VERSION ""

NS_ :

BS_:

BU_: Charger BMS

BO_ 2552626942 DM6: 1785 Vector__XXX

BO_ 2552561406 DM5: 0 Vector__XXX

BO_ 2552495870 DM4: 0 Vector__XXX

BO_ 2552430334 DM3: 2 Vector__XXX

BO_ 2552364798 DM2: 1785 Vector__XXX

BO_ 2552299262 DM1: 1785 Vector__XXX

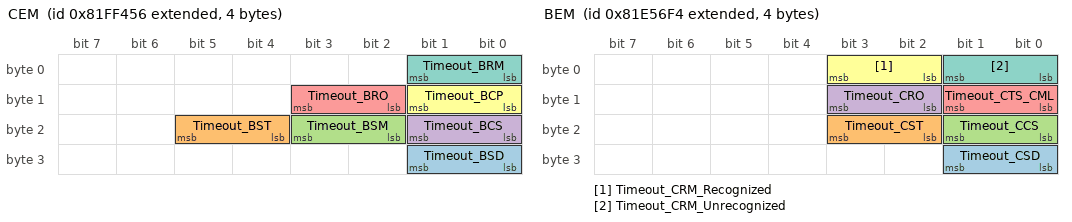
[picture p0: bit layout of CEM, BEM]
BO_ 2283795542 CEM: 4 Charger
 SG_ Timeout_BSD : 24|2@1+ (1,0) [0|3] ""  BMS
 SG_ Timeout_BST : 20|2@1+ (1,0) [0|3] ""  BMS
 SG_ Timeout_BSM : 18|2@1+ (1,0) [0|3] ""  BMS
 SG_ Timeout_BCS : 16|2@1+ (1,0) [0|3] ""  BMS
 SG_ Timeout_BRO : 10|2@1+ (1,0) [0|3] ""  BMS
 SG_ Timeout_BCP : 8|2@1+ (1,0) [0|3] ""  BMS
 SG_ Timeout_BRM : 0|2@1+ (1,0) [0|3] ""  BMS

BO_ 2283689716 BEM: 4 BMS
 SG_ Timeout_CSD : 24|2@1+ (1,0) [0|3] ""  Charger
 SG_ Timeout_CST : 18|2@1+ (1,0) [0|3] ""  Charger
 SG_ Timeout_CCS : 16|2@1+ (1,0) [0|3] ""  Charger
 SG_ Timeout_CRO : 10|2@1+ (1,0) [0|3] ""  Charger
 SG_ Timeout_CTS_CML : 8|2@1+ (1,0) [0|3] ""  Charger
 SG_ Timeout_CRM_Recognized : 2|2@1+ (1,0) [0|3] ""  Charger
 SG_ Timeout_CRM_Unrecognized : 0|2@1+ (1,0) [0|3] ""  Charger

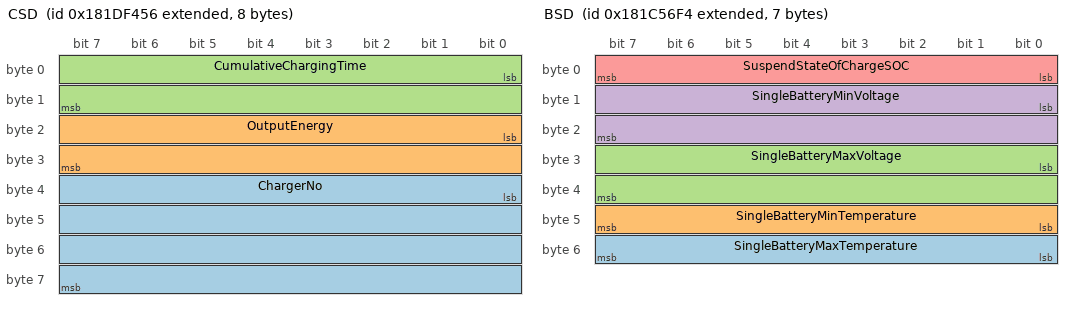
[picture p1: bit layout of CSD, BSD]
BO_ 2552099926 CSD: 8 Charger
 SG_ ChargerNo : 32|32@1+ (1,1) [1|4294967296] ""  BMS
 SG_ OutputEnergy : 16|16@1+ (0.1,0) [0|1000] "kWh"  BMS
 SG_ CumulativeChargingTime : 0|16@1+ (1,0) [0|600] "min"  BMS

BO_ 2551994100 BSD: 7 BMS
 SG_ SingleBatteryMaxTemperature : 48|8@1+ (1,-50) [-50|200] "°C"  Charger
 SG_ SingleBatteryMinTemperature : 40|8@1+ (1,-50) [-50|200] "°C"  Charger
 SG_ SingleBatteryMaxVoltage : 24|16@1+ (0.01,0) [0|24] "V"  Charger
 SG_ SingleBatteryMinVoltage : 8|16@1+ (0.01,0) [0|24] "V"  Charger
 SG_ SuspendStateOfChargeSOC : 0|8@1+ (1,0) [0|100] "%"  Charger

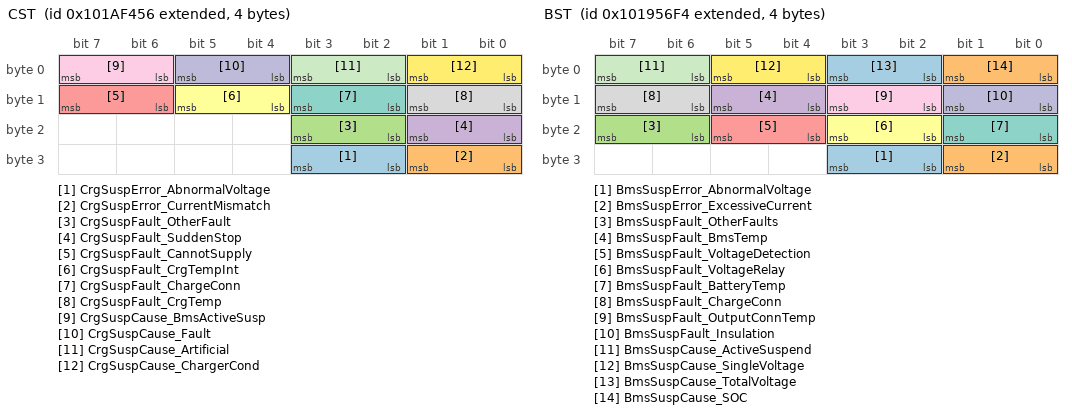
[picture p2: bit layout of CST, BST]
BO_ 2417685590 CST: 4 Charger
 SG_ CrgSuspError_AbnormalVoltage : 26|2@1+ (1,0) [0|3] ""  BMS
 SG_ CrgSuspError_CurrentMismatch : 24|2@1+ (1,0) [0|3] ""  BMS
 SG_ CrgSuspFault_OtherFault : 18|2@1+ (1,0) [0|3] ""  BMS
 SG_ CrgSuspFault_SuddenStop : 16|2@1+ (1,0) [0|3] ""  BMS
 SG_ CrgSuspFault_CannotSupply : 14|2@1+ (1,0) [0|3] ""  BMS
 SG_ CrgSuspFault_CrgTempInt : 12|2@1+ (1,0) [0|3] ""  BMS
 SG_ CrgSuspFault_ChargeConn : 10|2@1+ (1,0) [0|3] ""  BMS
 SG_ CrgSuspFault_CrgTemp : 8|2@1+ (1,0) [0|3] ""  BMS
 SG_ CrgSuspCause_BmsActiveSusp : 6|2@1+ (1,0) [0|3] ""  BMS
 SG_ CrgSuspCause_Fault : 4|2@1+ (1,0) [0|3] ""  BMS
 SG_ CrgSuspCause_Artificial : 2|2@1+ (1,0) [0|3] ""  BMS
 SG_ CrgSuspCause_ChargerCond : 0|2@1+ (1,0) [0|3] ""  BMS

BO_ 2417579764 BST: 4 BMS
 SG_ BmsSuspError_AbnormalVoltage : 26|2@1+ (1,0) [0|3] ""  Charger
 SG_ BmsSuspError_ExcessiveCurrent : 24|2@1+ (1,0) [0|3] ""  Charger
 SG_ BmsSuspFault_OtherFaults : 22|2@1+ (1,0) [0|3] ""  Charger
 SG_ BmsSuspFault_BmsTemp : 12|2@1+ (1,0) [0|3] ""  Charger
 SG_ BmsSuspFault_VoltageDetection : 20|2@1+ (1,0) [0|3] ""  Charger
 SG_ BmsSuspFault_VoltageRelay : 18|2@1+ (1,0) [0|3] ""  Charger
 SG_ BmsSuspFault_BatteryTemp : 16|2@1+ (1,0) [0|3] ""  Charger
 SG_ BmsSuspFault_ChargeConn : 14|2@1+ (1,0) [0|3] ""  Charger
 SG_ BmsSuspFault_OutputConnTemp : 10|2@1+ (1,0) [0|3] ""  Charger
 SG_ BmsSuspFault_Insulation : 8|2@1+ (1,0) [0|3] ""  Charger
 SG_ BmsSuspCause_ActiveSuspend : 6|2@1+ (1,0) [0|3] ""  Charger
 SG_ BmsSuspCause_SingleVoltage : 4|2@1+ (1,0) [0|3] ""  Charger
 SG_ BmsSuspCause_TotalVoltage : 2|2@1+ (1,0) [0|3] ""  Charger
 SG_ BmsSuspCause_SOC : 0|2@1+ (1,0) [0|3] ""  Charger

BO_ 2618775284 BSP: 16 BMS
 SG_ BatteryReserved16 : 120|8@1+ (1,0) [0|255] ""  Charger
 SG_ BatteryReserved15 : 112|8@1+ (1,0) [0|255] ""  Charger
 SG_ BatteryReserved14 : 104|8@1+ (1,0) [0|255] ""  Charger
 SG_ BatteryReserved13 : 96|8@1+ (1,0) [0|255] ""  Charger
 SG_ BatteryReserved12 : 88|8@1+ (1,0) [0|255] ""  Charger
 SG_ BatteryReserved11 : 80|8@1+ (1,0) [0|255] ""  Charger
 SG_ BatteryReserved10 : 72|8@1+ (1,0) [0|255] ""  Charger
 SG_ BatteryReserved09 : 64|8@1+ (1,0) [0|255] ""  Charger
 SG_ BatteryReserved08 : 56|8@1+ (1,0) [0|255] ""  Charger
 SG_ BatteryReserved07 : 48|8@1+ (1,0) [0|255] ""  Charger
 SG_ BatteryReserved06 : 40|8@1+ (1,0) [0|255] ""  Charger
 SG_ BatteryReserved05 : 32|8@1+ (1,0) [0|255] ""  Charger
 SG_ BatteryReserved04 : 24|8@1+ (1,0) [0|255] ""  Charger
 SG_ BatteryReserved03 : 16|8@1+ (1,0) [0|255] ""  Charger
 SG_ BatteryReserved02 : 8|8@1+ (1,0) [0|255] ""  Charger
 SG_ BatteryReserved01 : 0|8@1+ (1,0) [0|255] ""  Charger

BO_ 2618709748 BMT: 128 BMS
 SG_ BatteryTemperature128 : 1016|8@1+ (1,-50) [-50|200] "°C"  Charger
 SG_ BatteryTemperature127 : 1008|8@1+ (1,-50) [-50|200] "°C"  Charger
 SG_ BatteryTemperature126 : 1000|8@1+ (1,-50) [-50|200] "°C"  Charger
 SG_ BatteryTemperature125 : 992|8@1+ (1,-50) [-50|200] "°C"  Charger
 SG_ BatteryTemperature124 : 984|8@1+ (1,-50) [-50|200] "°C"  Charger
 SG_ BatteryTemperature123 : 976|8@1+ (1,-50) [-50|200] "°C"  Charger
 SG_ BatteryTemperature122 : 968|8@1+ (1,-50) [-50|200] "°C"  Charger
 SG_ BatteryTemperature121 : 960|8@1+ (1,-50) [-50|200] "°C"  Charger
 SG_ BatteryTemperature120 : 952|8@1+ (1,-50) [-50|200] "°C"  Charger
 SG_ BatteryTemperature119 : 944|8@1+ (1,-50) [-50|200] "°C"  Charger
 SG_ BatteryTemperature118 : 936|8@1+ (1,-50) [-50|200] "°C"  Charger
 SG_ BatteryTemperature117 : 928|8@1+ (1,-50) [-50|200] "°C"  Charger
 SG_ BatteryTemperature116 : 920|8@1+ (1,-50) [-50|200] "°C"  Charger
 SG_ BatteryTemperature115 : 912|8@1+ (1,-50) [-50|200] "°C"  Charger
 SG_ BatteryTemperature114 : 904|8@1+ (1,-50) [-50|200] "°C"  Charger
 SG_ BatteryTemperature113 : 896|8@1+ (1,-50) [-50|200] "°C"  Charger
 SG_ BatteryTemperature112 : 888|8@1+ (1,-50) [-50|200] "°C"  Charger
 SG_ BatteryTemperature111 : 880|8@1+ (1,-50) [-50|200] "°C"  Charger
 SG_ BatteryTemperature110 : 872|8@1+ (1,-50) [-50|200] "°C"  Charger
 SG_ BatteryTemperature109 : 864|8@1+ (1,-50) [-50|200] "°C"  Charger
 SG_ BatteryTemperature108 : 856|8@1+ (1,-50) [-50|200] "°C"  Charger
 SG_ BatteryTemperature107 : 848|8@1+ (1,-50) [-50|200] "°C"  Charger
 SG_ BatteryTemperature106 : 840|8@1+ (1,-50) [-50|200] "°C"  Charger
 SG_ BatteryTemperature105 : 832|8@1+ (1,-50) [-50|200] "°C"  Charger
 SG_ BatteryTemperature104 : 824|8@1+ (1,-50) [-50|200] "°C"  Charger
 SG_ BatteryTemperature103 : 816|8@1+ (1,-50) [-50|200] "°C"  Charger
 SG_ BatteryTemperature102 : 808|8@1+ (1,-50) [-50|200] "°C"  Charger
 SG_ BatteryTemperature101 : 800|8@1+ (1,-50) [-50|200] "°C"  Charger
 SG_ BatteryTemperature100 : 792|8@1+ (1,-50) [-50|200] "°C"  Charger
 SG_ BatteryTemperature099 : 784|8@1+ (1,-50) [-50|200] "°C"  Charger
 SG_ BatteryTemperature098 : 776|8@1+ (1,-50) [-50|200] "°C"  Charger
 SG_ BatteryTemperature097 : 768|8@1+ (1,-50) [-50|200] "°C"  Charger
 SG_ BatteryTemperature096 : 760|8@1+ (1,-50) [-50|200] "°C"  Charger
 SG_ BatteryTemperature095 : 752|8@1+ (1,-50) [-50|200] "°C"  Charger
 SG_ BatteryTemperature094 : 744|8@1+ (1,-50) [-50|200] "°C"  Charger
 SG_ BatteryTemperature093 : 736|8@1+ (1,-50) [-50|200] "°C"  Charger
 SG_ BatteryTemperature092 : 728|8@1+ (1,-50) [-50|200] "°C"  Charger
 SG_ BatteryTemperature091 : 720|8@1+ (1,-50) [-50|200] "°C"  Charger
 SG_ BatteryTemperature090 : 712|8@1+ (1,-50) [-50|200] "°C"  Charger
 SG_ BatteryTemperature089 : 704|8@1+ (1,-50) [-50|200] "°C"  Charger
 SG_ BatteryTemperature088 : 696|8@1+ (1,-50) [-50|200] "°C"  Charger
 SG_ BatteryTemperature087 : 688|8@1+ (1,-50) [-50|200] "°C"  Charger
 SG_ BatteryTemperature086 : 680|8@1+ (1,-50) [-50|200] "°C"  Charger
 SG_ BatteryTemperature085 : 672|8@1+ (1,-50) [-50|200] "°C"  Charger
 SG_ BatteryTemperature084 : 664|8@1+ (1,-50) [-50|200] "°C"  Charger
 SG_ BatteryTemperature083 : 656|8@1+ (1,-50) [-50|200] "°C"  Charger
 SG_ BatteryTemperature082 : 648|8@1+ (1,-50) [-50|200] "°C"  Charger
 SG_ BatteryTemperature081 : 640|8@1+ (1,-50) [-50|200] "°C"  Charger
 SG_ BatteryTemperature080 : 632|8@1+ (1,-50) [-50|200] "°C"  Charger
 SG_ BatteryTemperature079 : 624|8@1+ (1,-50) [-50|200] "°C"  Charger
 SG_ BatteryTemperature078 : 616|8@1+ (1,-50) [-50|200] "°C"  Charger
 SG_ BatteryTemperature077 : 608|8@1+ (1,-50) [-50|200] "°C"  Charger
 SG_ BatteryTemperature076 : 600|8@1+ (1,-50) [-50|200] "°C"  Charger
 SG_ BatteryTemperature075 : 592|8@1+ (1,-50) [-50|200] "°C"  Charger
 SG_ BatteryTemperature074 : 584|8@1+ (1,-50) [-50|200] "°C"  Charger
 SG_ BatteryTemperature073 : 576|8@1+ (1,-50) [-50|200] "°C"  Charger
 SG_ BatteryTemperature072 : 568|8@1+ (1,-50) [-50|200] "°C"  Charger
 SG_ BatteryTemperature071 : 560|8@1+ (1,-50) [-50|200] "°C"  Charger
 SG_ BatteryTemperature070 : 552|8@1+ (1,-50) [-50|200] "°C"  Charger
 SG_ BatteryTemperature069 : 544|8@1+ (1,-50) [-50|200] "°C"  Charger
 SG_ BatteryTemperature068 : 536|8@1+ (1,-50) [-50|200] "°C"  Charger
 SG_ BatteryTemperature067 : 528|8@1+ (1,-50) [-50|200] "°C"  Charger
 SG_ BatteryTemperature066 : 520|8@1+ (1,-50) [-50|200] "°C"  Charger
 SG_ BatteryTemperature065 : 512|8@1+ (1,-50) [-50|200] "°C"  Charger
 SG_ BatteryTemperature064 : 504|8@1+ (1,-50) [-50|200] "°C"  Charger
 SG_ BatteryTemperature063 : 496|8@1+ (1,-50) [-50|200] "°C"  Charger
 SG_ BatteryTemperature062 : 488|8@1+ (1,-50) [-50|200] "°C"  Charger
 SG_ BatteryTemperature061 : 480|8@1+ (1,-50) [-50|200] "°C"  Charger
 SG_ BatteryTemperature060 : 472|8@1+ (1,-50) [-50|200] "°C"  Charger
 SG_ BatteryTemperature059 : 464|8@1+ (1,-50) [-50|200] "°C"  Charger
 SG_ BatteryTemperature058 : 456|8@1+ (1,-50) [-50|200] "°C"  Charger
 SG_ BatteryTemperature057 : 448|8@1+ (1,-50) [-50|200] "°C"  Charger
 SG_ BatteryTemperature056 : 440|8@1+ (1,-50) [-50|200] "°C"  Charger
 SG_ BatteryTemperature055 : 432|8@1+ (1,-50) [-50|200] "°C"  Charger
 SG_ BatteryTemperature054 : 424|8@1+ (1,-50) [-50|200] "°C"  Charger
 SG_ BatteryTemperature053 : 416|8@1+ (1,-50) [-50|200] "°C"  Charger
 SG_ BatteryTemperature052 : 408|8@1+ (1,-50) [-50|200] "°C"  Charger
 SG_ BatteryTemperature051 : 400|8@1+ (1,-50) [-50|200] "°C"  Charger
 SG_ BatteryTemperature050 : 392|8@1+ (1,-50) [-50|200] "°C"  Charger
 SG_ BatteryTemperature049 : 384|8@1+ (1,-50) [-50|200] "°C"  Charger
 SG_ BatteryTemperature048 : 376|8@1+ (1,-50) [-50|200] "°C"  Charger
 SG_ BatteryTemperature047 : 368|8@1+ (1,-50) [-50|200] "°C"  Charger
 SG_ BatteryTemperature046 : 360|8@1+ (1,-50) [-50|200] "°C"  Charger
 SG_ BatteryTemperature045 : 352|8@1+ (1,-50) [-50|200] "°C"  Charger
 SG_ BatteryTemperature044 : 344|8@1+ (1,-50) [-50|200] "°C"  Charger
 SG_ BatteryTemperature043 : 336|8@1+ (1,-50) [-50|200] "°C"  Charger
 SG_ BatteryTemperature042 : 328|8@1+ (1,-50) [-50|200] "°C"  Charger
 SG_ BatteryTemperature041 : 320|8@1+ (1,-50) [-50|200] "°C"  Charger
 SG_ BatteryTemperature040 : 312|8@1+ (1,-50) [-50|200] "°C"  Charger
 SG_ BatteryTemperature039 : 304|8@1+ (1,-50) [-50|200] "°C"  Charger
 SG_ BatteryTemperature038 : 296|8@1+ (1,-50) [-50|200] "°C"  Charger
 SG_ BatteryTemperature037 : 288|8@1+ (1,-50) [-50|200] "°C"  Charger
 SG_ BatteryTemperature036 : 280|8@1+ (1,-50) [-50|200] "°C"  Charger
 SG_ BatteryTemperature035 : 272|8@1+ (1,-50) [-50|200] "°C"  Charger
 SG_ BatteryTemperature034 : 264|8@1+ (1,-50) [-50|200] "°C"  Charger
 SG_ BatteryTemperature033 : 256|8@1+ (1,-50) [-50|200] "°C"  Charger
 SG_ BatteryTemperature032 : 248|8@1+ (1,-50) [-50|200] "°C"  Charger
 SG_ BatteryTemperature031 : 240|8@1+ (1,-50) [-50|200] "°C"  Charger
 SG_ BatteryTemperature030 : 232|8@1+ (1,-50) [-50|200] "°C"  Charger
 SG_ BatteryTemperature029 : 224|8@1+ (1,-50) [-50|200] "°C"  Charger
 SG_ BatteryTemperature028 : 216|8@1+ (1,-50) [-50|200] "°C"  Charger
 SG_ BatteryTemperature027 : 208|8@1+ (1,-50) [-50|200] "°C"  Charger
 SG_ BatteryTemperature026 : 200|8@1+ (1,-50) [-50|200] "°C"  Charger
 SG_ BatteryTemperature025 : 192|8@1+ (1,-50) [-50|200] "°C"  Charger
 SG_ BatteryTemperature024 : 184|8@1+ (1,-50) [-50|200] "°C"  Charger
 SG_ BatteryTemperature023 : 176|8@1+ (1,-50) [-50|200] "°C"  Charger
 SG_ BatteryTemperature022 : 168|8@1+ (1,-50) [-50|200] "°C"  Charger
 SG_ BatteryTemperature021 : 160|8@1+ (1,-50) [-50|200] "°C"  Charger
 SG_ BatteryTemperature020 : 152|8@1+ (1,-50) [-50|200] "°C"  Charger
 SG_ BatteryTemperature019 : 144|8@1+ (1,-50) [-50|200] "°C"  Charger
 SG_ BatteryTemperature018 : 136|8@1+ (1,-50) [-50|200] "°C"  Charger
 SG_ BatteryTemperature017 : 128|8@1+ (1,-50) [-50|200] "°C"  Charger
 SG_ BatteryTemperature016 : 120|8@1+ (1,-50) [-50|200] "°C"  Charger
 SG_ BatteryTemperature015 : 112|8@1+ (1,-50) [-50|200] "°C"  Charger
 SG_ BatteryTemperature014 : 104|8@1+ (1,-50) [-50|200] "°C"  Charger
 SG_ BatteryTemperature013 : 96|8@1+ (1,-50) [-50|200] "°C"  Charger
 SG_ BatteryTemperature012 : 88|8@1+ (1,-50) [-50|200] "°C"  Charger
 SG_ BatteryTemperature011 : 80|8@1+ (1,-50) [-50|200] "°C"  Charger
 SG_ BatteryTemperature010 : 72|8@1+ (1,-50) [-50|200] "°C"  Charger
 SG_ BatteryTemperature009 : 64|8@1+ (1,-50) [-50|200] "°C"  Charger
 SG_ BatteryTemperature008 : 56|8@1+ (1,-50) [-50|200] "°C"  Charger
 SG_ BatteryTemperature007 : 48|8@1+ (1,-50) [-50|200] "°C"  Charger
 SG_ BatteryTemperature006 : 40|8@1+ (1,-50) [-50|200] "°C"  Charger
 SG_ BatteryTemperature005 : 32|8@1+ (1,-50) [-50|200] "°C"  Charger
 SG_ BatteryTemperature004 : 24|8@1+ (1,-50) [-50|200] "°C"  Charger
 SG_ BatteryTemperature003 : 16|8@1+ (1,-50) [-50|200] "°C"  Charger
 SG_ BatteryTemperature002 : 8|8@1+ (1,-50) [-50|200] "°C"  Charger
 SG_ BatteryTemperature001 : 0|8@1+ (1,-50) [-50|200] "°C"  Charger

CM_ "J1939 messages without part -7x";
CM_ BO_ 2552626942 "Freeze frame parameter

Attention: Incomplete signal set!";
CM_ BO_ 2552561406 "Clear/reset of historic fault code";
CM_ BO_ 2552495870 "Clear/reset of current fault code";
CM_ BO_ 2552430334 "Diagnose ready

Attention: Incomplete signal set!";
CM_ BO_ 2552364798 "Historic fault code

Attention: Incomplete signal set!";
CM_ BO_ 2552299262 "Current fault code

Attention: Incomplete signal set!";
CM_ BO_ 2283795542 "Charger's error message";
CM_ SG_ 2283795542 Timeout_BSD "Receive timeout of BMS's charging statistics message (<00>:=normal; <01>:=timeout; <10>:=untrusted state)";
CM_ SG_ 2283795542 Timeout_BST "Receive timeout of BMS's charging suspension message (<00>:=normal; <01>:=timeout; <10>:=untrusted state)";
CM_ SG_ 2283795542 Timeout_BSM "Receive timeout of battery charging requirement message (<00>:=normal; <01>:=timeout; <10>:=untrusted state)";
CM_ SG_ 2283795542 Timeout_BCS "Receive timeout of overall battery charging state message (<00>:=normal; <01>:=timeout; <10>:=untrusted state)";
CM_ SG_ 2283795542 Timeout_BRO "Receive timeout of BMS's charging preparation completion message (<00>:=normal; <01>:=timeout; <10>:=untrusted state)";
CM_ SG_ 2283795542 Timeout_BCP "Receive timeout of battery charging parameter message (<00>:=normal; <01>:=timeout; <10>:=untrusted state)";
CM_ SG_ 2283795542 Timeout_BRM "Receive timeout of BMS and vehicle recognition message (<00>:=normal; <01>:=timeout; <10>:=untrusted state)";
CM_ BO_ 2283689716 "BMS's error message";
CM_ SG_ 2283689716 Timeout_CSD "Receive timeout of charger's charging statistics message (<00>:=normal; <01>:=timeout; <10>:=untrusted state)";
CM_ SG_ 2283689716 Timeout_CST "Receive timeout of charger's charging suspension message (<00>:=normal; <01>:=timeout; <10>:=untrusted state)";
CM_ SG_ 2283689716 Timeout_CCS "Receive  timeout  of  charger's  charging  state  message (<00>:=normal; <01>:=timeout; <10>:=untrusted state)";
CM_ SG_ 2283689716 Timeout_CRO "Receive  timeout  of  charger's  charging  preparation  completion message (<00>:=normal; <01>:=timeout; <10>:=untrusted state)";
CM_ SG_ 2283689716 Timeout_CTS_CML "Receive  timeout  of  charger  time  synchronization  message  and charger  maximum  output  capacity  message  (<00>:=normal; <01>:=timeout; <10>:=untrusted state)";
CM_ SG_ 2283689716 Timeout_CRM_Recognized "Receive timeout of SPN2560=0×AA charger recognition message (<00>:=normal; <01>:=timeout; <10>:=untrusted state)";
CM_ SG_ 2283689716 Timeout_CRM_Unrecognized "Receive timeout of SPN2560=0×00 charger recognition message (<00>:=normal; <01>:=timeout; <10>:=untrusted state)";
CM_ BO_ 2552099926 "Charger's statistical data";
CM_ SG_ 2552099926 ChargerNo "Charger No., 1/bit; 1 offset; data scope: 0~0xFFFFFFFF";
CM_ SG_ 2552099926 OutputEnergy "Output energy (kW·h)";
CM_ SG_ 2552099926 CumulativeChargingTime "Cumulative charging time (min)";
CM_ BO_ 2551994100 "BMS statistical data";
CM_ SG_ 2551994100 SingleBatteryMaxTemperature "Maximum temperature of power storage battery (°C)";
CM_ SG_ 2551994100 SingleBatteryMinTemperature "Minimum temperature of power storage battery (°C)";
CM_ SG_ 2551994100 SingleBatteryMaxVoltage "Maximum voltage of single power storage battery (V)";
CM_ SG_ 2551994100 SingleBatteryMinVoltage "Minimum voltage of single power storage battery (V)";
CM_ SG_ 2551994100 SuspendStateOfChargeSOC "Suspend state-of-charge SOC (%)";
CM_ BO_ 2417685590 "Charger suspending charging";
CM_ SG_ 2417685590 CrgSuspError_AbnormalVoltage "Error cause for charger suspending charging

voltage is abnormal";
CM_ SG_ 2417685590 CrgSuspError_CurrentMismatch "Error cause for charger suspending charging

current mismatching";
CM_ SG_ 2417685590 CrgSuspFault_OtherFault "Fault cause for charger suspending charging

other fault";
CM_ SG_ 2417685590 CrgSuspFault_SuddenStop "Fault cause for charger suspending charging

sudden stop of charger";
CM_ SG_ 2417685590 CrgSuspFault_CannotSupply "Fault cause for charger suspending charging

the required electric quantity cannot be transmitted";
CM_ SG_ 2417685590 CrgSuspFault_CrgTempInt "Fault cause for charger suspending charging

charger is over-temperature at the internal part";
CM_ SG_ 2417685590 CrgSuspFault_ChargeConn "Fault cause for charger suspending charging

charging connector fault";
CM_ SG_ 2417685590 CrgSuspFault_CrgTemp "Fault cause for charger suspending charging

charger over-temperature";
CM_ SG_ 2417685590 CrgSuspCause_BmsActiveSusp "Cause for charger suspending charging - BMS actively suspends";
CM_ SG_ 2417685590 CrgSuspCause_Fault "Cause for charger suspending charging - fault suspension";
CM_ SG_ 2417685590 CrgSuspCause_Artificial "Cause for charger suspending charging - suspends artificially";
CM_ SG_ 2417685590 CrgSuspCause_ChargerCond "Cause for charger suspending charging - suspends due to reaching the condition set by charger";
CM_ BO_ 2417579764 "BMS suspending charging";
CM_ SG_ 2417579764 BmsSuspError_AbnormalVoltage "Error cause for BMS suspending charging

voltage is abnormal";
CM_ SG_ 2417579764 BmsSuspError_ExcessiveCurrent "Error cause for BMS suspending charging

excessive current";
CM_ SG_ 2417579764 BmsSuspFault_OtherFaults "Fault cause for BMS suspending charging

other faults";
CM_ SG_ 2417579764 BmsSuspFault_BmsTemp "Fault cause for BMS suspending charging

BMS component and output connector over-temperature";
CM_ SG_ 2417579764 BmsSuspFault_VoltageDetection "Fault cause for BMS suspending charging

voltage detection fault at check point 2";
CM_ SG_ 2417579764 BmsSuspFault_VoltageRelay "Fault cause for BMS suspending charging

high voltage relay fault";
CM_ SG_ 2417579764 BmsSuspFault_BatteryTemp "Fault cause for BMS suspending charging

battery set over-temperature";
CM_ SG_ 2417579764 BmsSuspFault_ChargeConn "Fault cause for BMS suspending charging

charging connector fault";
CM_ SG_ 2417579764 BmsSuspFault_OutputConnTemp "Fault cause for BMS suspending charging

output connector over-temperature";
CM_ SG_ 2417579764 BmsSuspFault_Insulation "Fault cause for BMS suspending charging

insulation fault";
CM_ SG_ 2417579764 BmsSuspCause_ActiveSuspend "Cause for BMS suspending charging

charger actively suspends";
CM_ SG_ 2417579764 BmsSuspCause_SingleVoltage "Cause for BMS suspending charging

reach the setting value of single voltage";
CM_ SG_ 2417579764 BmsSuspCause_TotalVoltage "Cause for BMS suspending charging

reach the setting value of total voltage ";
CM_ SG_ 2417579764 BmsSuspCause_SOC "Cause for BMS suspending charging

reach the required SOC target value";
CM_ BO_ 2618775284 "Reserved message of power storage battery";
CM_ SG_ 2618775284 BatteryReserved16 "Power storage battery reserved field 16";
CM_ SG_ 2618775284 BatteryReserved15 "Power storage battery reserved field 15";
CM_ SG_ 2618775284 BatteryReserved14 "Power storage battery reserved field 14";
CM_ SG_ 2618775284 BatteryReserved13 "Power storage battery reserved field 13";
CM_ SG_ 2618775284 BatteryReserved12 "Power storage battery reserved field 12";
CM_ SG_ 2618775284 BatteryReserved11 "Power storage battery reserved field 11";
CM_ SG_ 2618775284 BatteryReserved10 "Power storage battery reserved field 10";
CM_ SG_ 2618775284 BatteryReserved09 "Power storage battery reserved field 9";
CM_ SG_ 2618775284 BatteryReserved08 "Power storage battery reserved field 8";
CM_ SG_ 2618775284 BatteryReserved07 "Power storage battery reserved field 7";
CM_ SG_ 2618775284 BatteryReserved06 "Power storage battery reserved field 6";
CM_ SG_ 2618775284 BatteryReserved05 "Power storage battery reserved field 5";
CM_ SG_ 2618775284 BatteryReserved04 "Power storage battery reserved field 4";
CM_ SG_ 2618775284 BatteryReserved03 "Power storage battery reserved field 3";
CM_ SG_ 2618775284 BatteryReserved02 "Power storage battery reserved field 2";
CM_ SG_ 2618775284 BatteryReserved01 "Power storage battery reserved field 1";
CM_ BO_ 2618709748 "Temperature of power storage battery";
CM_ SG_ 2618709748 BatteryTemperature128 "Power storage battery temperature 128";
CM_ SG_ 2618709748 BatteryTemperature127 "Power storage battery temperature 127";
CM_ SG_ 2618709748 BatteryTemperature126 "Power storage battery temperature 126";
CM_ SG_ 2618709748 BatteryTemperature125 "Power storage battery temperature 125";
CM_ SG_ 2618709748 BatteryTemperature124 "Power storage battery temperature 124";
CM_ SG_ 2618709748 BatteryTemperature123 "Power storage battery temperature 123";
CM_ SG_ 2618709748 BatteryTemperature122 "Power storage battery temperature 122";
CM_ SG_ 2618709748 BatteryTemperature121 "Power storage battery temperature 121";
CM_ SG_ 2618709748 BatteryTemperature120 "Power storage battery temperature 120";
CM_ SG_ 2618709748 BatteryTemperature119 "Power storage battery temperature 119";
CM_ SG_ 2618709748 BatteryTemperature118 "Power storage battery temperature 118";
CM_ SG_ 2618709748 BatteryTemperature117 "Power storage battery temperature 117";
CM_ SG_ 2618709748 BatteryTemperature116 "Power storage battery temperature 116";
CM_ SG_ 2618709748 BatteryTemperature115 "Power storage battery temperature 115";
CM_ SG_ 2618709748 BatteryTemperature114 "Power storage battery temperature 114";
CM_ SG_ 2618709748 BatteryTemperature113 "Power storage battery temperature 113";
CM_ SG_ 2618709748 BatteryTemperature112 "Power storage battery temperature 112";
CM_ SG_ 2618709748 BatteryTemperature111 "Power storage battery temperature 111";
CM_ SG_ 2618709748 BatteryTemperature110 "Power storage battery temperature 110";
CM_ SG_ 2618709748 BatteryTemperature109 "Power storage battery temperature 109";
CM_ SG_ 2618709748 BatteryTemperature108 "Power storage battery temperature 108";
CM_ SG_ 2618709748 BatteryTemperature107 "Power storage battery temperature 107";
CM_ SG_ 2618709748 BatteryTemperature106 "Power storage battery temperature 106";
CM_ SG_ 2618709748 BatteryTemperature105 "Power storage battery temperature 105";
CM_ SG_ 2618709748 BatteryTemperature104 "Power storage battery temperature 104";
CM_ SG_ 2618709748 BatteryTemperature103 "Power storage battery temperature 103";
CM_ SG_ 2618709748 BatteryTemperature102 "Power storage battery temperature 102";
CM_ SG_ 2618709748 BatteryTemperature101 "Power storage battery temperature 101";
CM_ SG_ 2618709748 BatteryTemperature100 "Power storage battery temperature 100";
CM_ SG_ 2618709748 BatteryTemperature099 "Power storage battery temperature 99";
CM_ SG_ 2618709748 BatteryTemperature098 "Power storage battery temperature 98";
CM_ SG_ 2618709748 BatteryTemperature097 "Power storage battery temperature 97";
CM_ SG_ 2618709748 BatteryTemperature096 "Power storage battery temperature 96";
CM_ SG_ 2618709748 BatteryTemperature095 "Power storage battery temperature 95";
CM_ SG_ 2618709748 BatteryTemperature094 "Power storage battery temperature 94";
CM_ SG_ 2618709748 BatteryTemperature093 "Power storage battery temperature 93";
CM_ SG_ 2618709748 BatteryTemperature092 "Power storage battery temperature 92";
CM_ SG_ 2618709748 BatteryTemperature091 "Power storage battery temperature 91";
CM_ SG_ 2618709748 BatteryTemperature090 "Power storage battery temperature 90";
CM_ SG_ 2618709748 BatteryTemperature089 "Power storage battery temperature 89";
CM_ SG_ 2618709748 BatteryTemperature088 "Power storage battery temperature 88";
CM_ SG_ 2618709748 BatteryTemperature087 "Power storage battery temperature 87";
CM_ SG_ 2618709748 BatteryTemperature086 "Power storage battery temperature 86";
CM_ SG_ 2618709748 BatteryTemperature085 "Power storage battery temperature 85";
CM_ SG_ 2618709748 BatteryTemperature084 "Power storage battery temperature 84";
CM_ SG_ 2618709748 BatteryTemperature083 "Power storage battery temperature 83";
CM_ SG_ 2618709748 BatteryTemperature082 "Power storage battery temperature 82";
CM_ SG_ 2618709748 BatteryTemperature081 "Power storage battery temperature 81";
CM_ SG_ 2618709748 BatteryTemperature080 "Power storage battery temperature 80";
CM_ SG_ 2618709748 BatteryTemperature079 "Power storage battery temperature 79";
CM_ SG_ 2618709748 BatteryTemperature078 "Power storage battery temperature 78";
CM_ SG_ 2618709748 BatteryTemperature077 "Power storage battery temperature 77";
CM_ SG_ 2618709748 BatteryTemperature076 "Power storage battery temperature 76";
CM_ SG_ 2618709748 BatteryTemperature075 "Power storage battery temperature 75";
CM_ SG_ 2618709748 BatteryTemperature074 "Power storage battery temperature 74";
CM_ SG_ 2618709748 BatteryTemperature073 "Power storage battery temperature 73";
CM_ SG_ 2618709748 BatteryTemperature072 "Power storage battery temperature 72";
CM_ SG_ 2618709748 BatteryTemperature071 "Power storage battery temperature 71";
CM_ SG_ 2618709748 BatteryTemperature070 "Power storage battery temperature 70";
CM_ SG_ 2618709748 BatteryTemperature069 "Power storage battery temperature 69";
CM_ SG_ 2618709748 BatteryTemperature068 "Power storage battery temperature 68";
CM_ SG_ 2618709748 BatteryTemperature067 "Power storage battery temperature 67";
CM_ SG_ 2618709748 BatteryTemperature066 "Power storage battery temperature 66";
CM_ SG_ 2618709748 BatteryTemperature065 "Power storage battery temperature 65";
CM_ SG_ 2618709748 BatteryTemperature064 "Power storage battery temperature 64";
CM_ SG_ 2618709748 BatteryTemperature063 "Power storage battery temperature 63";
CM_ SG_ 2618709748 BatteryTemperature062 "Power storage battery temperature 62";
CM_ SG_ 2618709748 BatteryTemperature061 "Power storage battery temperature 61";
CM_ SG_ 2618709748 BatteryTemperature060 "Power storage battery temperature 60";
CM_ SG_ 2618709748 BatteryTemperature059 "Power storage battery temperature 59";
CM_ SG_ 2618709748 BatteryTemperature058 "Power storage battery temperature 58";
CM_ SG_ 2618709748 BatteryTemperature057 "Power storage battery temperature 57";
CM_ SG_ 2618709748 BatteryTemperature056 "Power storage battery temperature 56";
CM_ SG_ 2618709748 BatteryTemperature055 "Power storage battery temperature 55";
CM_ SG_ 2618709748 BatteryTemperature054 "Power storage battery temperature 54";
CM_ SG_ 2618709748 BatteryTemperature053 "Power storage battery temperature 53";
CM_ SG_ 2618709748 BatteryTemperature052 "Power storage battery temperature 52";
CM_ SG_ 2618709748 BatteryTemperature051 "Power storage battery temperature 51";
CM_ SG_ 2618709748 BatteryTemperature050 "Power storage battery temperature 50";
CM_ SG_ 2618709748 BatteryTemperature049 "Power storage battery temperature 49";
CM_ SG_ 2618709748 BatteryTemperature048 "Power storage battery temperature 48";
CM_ SG_ 2618709748 BatteryTemperature047 "Power storage battery temperature 47";
CM_ SG_ 2618709748 BatteryTemperature046 "Power storage battery temperature 46";
CM_ SG_ 2618709748 BatteryTemperature045 "Power storage battery temperature 45";
CM_ SG_ 2618709748 BatteryTemperature044 "Power storage battery temperature 44";
CM_ SG_ 2618709748 BatteryTemperature043 "Power storage battery temperature 43";
CM_ SG_ 2618709748 BatteryTemperature042 "Power storage battery temperature 42";
CM_ SG_ 2618709748 BatteryTemperature041 "Power storage battery temperature 41";
CM_ SG_ 2618709748 BatteryTemperature040 "Power storage battery temperature 40";
CM_ SG_ 2618709748 BatteryTemperature039 "Power storage battery temperature 39";
CM_ SG_ 2618709748 BatteryTemperature038 "Power storage battery temperature 38";
CM_ SG_ 2618709748 BatteryTemperature037 "Power storage battery temperature 37";
CM_ SG_ 2618709748 BatteryTemperature036 "Power storage battery temperature 36";
CM_ SG_ 2618709748 BatteryTemperature035 "Power storage battery temperature 35";
CM_ SG_ 2618709748 BatteryTemperature034 "Power storage battery temperature 34";
CM_ SG_ 2618709748 BatteryTemperature033 "Power storage battery temperature 33";
CM_ SG_ 2618709748 BatteryTemperature032 "Power storage battery temperature 32";
CM_ SG_ 2618709748 BatteryTemperature031 "Power storage battery temperature 31";
CM_ SG_ 2618709748 BatteryTemperature030 "Power storage battery temperature 30";
CM_ SG_ 2618709748 BatteryTemperature029 "Power storage battery temperature 29";
CM_ SG_ 2618709748 BatteryTemperature028 "Power storage battery temperature 28";
CM_ SG_ 2618709748 BatteryTemperature027 "Power storage battery temperature 27";
CM_ SG_ 2618709748 BatteryTemperature026 "Power storage battery temperature 26";
CM_ SG_ 2618709748 BatteryTemperature025 "Power storage battery temperature 25";
CM_ SG_ 2618709748 BatteryTemperature024 "Power storage battery temperature 24";
CM_ SG_ 2618709748 BatteryTemperature023 "Power storage battery temperature 23";
CM_ SG_ 2618709748 BatteryTemperature022 "Power storage battery temperature 22";
CM_ SG_ 2618709748 BatteryTemperature021 "Power storage battery temperature 21";
CM_ SG_ 2618709748 BatteryTemperature020 "Power storage battery temperature 20";
CM_ SG_ 2618709748 BatteryTemperature019 "Power storage battery temperature 19";
CM_ SG_ 2618709748 BatteryTemperature018 "Power storage battery temperature 18";
CM_ SG_ 2618709748 BatteryTemperature017 "Power storage battery temperature 17";
CM_ SG_ 2618709748 BatteryTemperature016 "Power storage battery temperature 16";
CM_ SG_ 2618709748 BatteryTemperature015 "Power storage battery temperature 15";
CM_ SG_ 2618709748 BatteryTemperature014 "Power storage battery temperature 14";
CM_ SG_ 2618709748 BatteryTemperature013 "Power storage battery temperature 13";
CM_ SG_ 2618709748 BatteryTemperature012 "Power storage battery temperature 12";
CM_ SG_ 2618709748 BatteryTemperature011 "Power storage battery temperature 11";
CM_ SG_ 2618709748 BatteryTemperature010 "Power storage battery temperature 10";
CM_ SG_ 2618709748 BatteryTemperature009 "Power storage battery temperature 9";
CM_ SG_ 2618709748 BatteryTemperature008 "Power storage battery temperature 8";
CM_ SG_ 2618709748 BatteryTemperature007 "Power storage battery temperature 7";
CM_ SG_ 2618709748 BatteryTemperature006 "Power storage battery temperature 6";
CM_ SG_ 2618709748 BatteryTemperature005 "Power storage battery temperature 5";
CM_ SG_ 2618709748 BatteryTemperature004 "Power storage battery temperature 4";
CM_ SG_ 2618709748 BatteryTemperature003 "Power storage battery temperature 3";
CM_ SG_ 2618709748 BatteryTemperature002 "Power storage battery temperature 2";
CM_ SG_ 2618709748 BatteryTemperature001 "Power storage battery temperature 1";
BA_DEF_  "DBName" STRING ;
BA_DEF_ SG_  "SigType" ENUM  "Default","Range","RangeSigned","ASCII","Discrete","Control","ReferencePGN","DTC","StringDelimiter","StringLength","StringLengthControl","MessageCounter","MessageChecksum";
BA_DEF_ SG_  "GenSigStartValue" INT 0 2147483647;
BA_DEF_ SG_  "GenSigSendType" ENUM  "Cyclic","OnWrite","OnWriteWithRepetition","OnChange","OnChangeWithRepetition","IfActive","IfActiveWithRepetition","NoSigSendType";
BA_DEF_ SG_  "GenSigILSupport" ENUM  "No","Yes";
BA_DEF_ SG_  "GenSigEVName" STRING ;
BA_DEF_ SG_  "SPN" INT 0 524287;
BA_DEF_ BO_  "TpJ1939VarDlc" ENUM  "No","Yes";
BA_DEF_ BO_  "GenMsgILSupport" ENUM  "No","Yes";
BA_DEF_ BO_  "GenMsgRequestable" INT 0 1;
BA_DEF_ BO_  "GenMsgSendType" ENUM  "cyclic","NotUsed","NotUsed","NotUsed","NotUsed","NotUsed","NotUsed","IfActive","noMsgSendType";
BA_DEF_ BO_  "VFrameFormat" ENUM  "StandardCAN","ExtendedCAN","reserved","J1939PG";
BA_DEF_ BO_  "GenMsgCycleTime" INT 0 3600000;
BA_DEF_ BU_  "NmStationAddress" INT 0 255;
BA_DEF_ BU_  "NmJ1939Function" INT 0 255;
BA_DEF_ BU_  "NmJ1939ManufacturerCode" INT 0 2047;
BA_DEF_  "SAE_J1939_DA_SpecVersion" STRING ;
BA_DEF_  "SAE_J1939_81_SpecVersion" STRING ;
BA_DEF_  "DatabaseVersion" STRING ;
BA_DEF_  "BusType" STRING ;
BA_DEF_  "ProtocolType" STRING ;
BA_DEF_  "SAE_J1939_21_SpecVersion" STRING ;
BA_DEF_DEF_  "DBName" "";
BA_DEF_DEF_  "SigType" "Default";
BA_DEF_DEF_  "GenSigStartValue" 0;
BA_DEF_DEF_  "GenSigSendType" "NoSigSendType";
BA_DEF_DEF_  "GenSigILSupport" "Yes";
BA_DEF_DEF_  "GenSigEVName" "Env@Nodename_@Signame";
BA_DEF_DEF_  "SPN" 0;
BA_DEF_DEF_  "TpJ1939VarDlc" "No";
BA_DEF_DEF_  "GenMsgILSupport" "Yes";
BA_DEF_DEF_  "GenMsgRequestable" 1;
BA_DEF_DEF_  "GenMsgSendType" "noMsgSendType";
BA_DEF_DEF_  "VFrameFormat" "J1939PG";
BA_DEF_DEF_  "GenMsgCycleTime" 0;
BA_DEF_DEF_  "NmStationAddress" 254;
BA_DEF_DEF_  "NmJ1939Function" 0;
BA_DEF_DEF_  "NmJ1939ManufacturerCode" 0;
BA_DEF_DEF_  "SAE_J1939_DA_SpecVersion" "";
BA_DEF_DEF_  "SAE_J1939_81_SpecVersion" "";
BA_DEF_DEF_  "DatabaseVersion" "";
BA_DEF_DEF_  "BusType" "";
BA_DEF_DEF_  "ProtocolType" "";
BA_DEF_DEF_  "SAE_J1939_21_SpecVersion" "";
BA_ "SAE_J1939_DA_SpecVersion" "2015-01";
BA_ "SAE_J1939_81_SpecVersion" "2012-05";
BA_ "DatabaseVersion" "8.5";
BA_ "BusType" "CAN";
BA_ "ProtocolType" "J1939";
BA_ "SAE_J1939_21_SpecVersion" "2006-10";
BA_ "DBName" "gbt27930";
BA_ "NmStationAddress" BU_ Charger 86;
BA_ "NmJ1939Function" BU_ Charger 31;
BA_ "NmJ1939ManufacturerCode" BU_ Charger 1861;
BA_ "NmStationAddress" BU_ BMS 244;
BA_ "NmJ1939Function" BU_ BMS 4;
BA_ "NmJ1939ManufacturerCode" BU_ BMS 1861;
BA_ "TpJ1939VarDlc" BO_ 2552626942 1;
BA_ "GenMsgILSupport" BO_ 2552626942 0;
BA_ "GenMsgILSupport" BO_ 2552561406 0;
BA_ "GenMsgILSupport" BO_ 2552495870 0;
BA_ "GenMsgILSupport" BO_ 2552430334 0;
BA_ "TpJ1939VarDlc" BO_ 2552364798 1;
BA_ "GenMsgILSupport" BO_ 2552364798 0;
BA_ "TpJ1939VarDlc" BO_ 2552299262 1;
BA_ "GenMsgILSupport" BO_ 2552299262 0;
BA_ "GenMsgILSupport" BO_ 2283795542 0;
BA_ "GenMsgRequestable" BO_ 2283795542 0;
BA_ "GenMsgSendType" BO_ 2283795542 0;
BA_ "GenMsgCycleTime" BO_ 2283795542 250;
BA_ "GenMsgILSupport" BO_ 2283689716 0;
BA_ "GenMsgRequestable" BO_ 2283689716 0;
BA_ "GenMsgSendType" BO_ 2283689716 0;
BA_ "GenMsgCycleTime" BO_ 2283689716 250;
BA_ "GenMsgILSupport" BO_ 2552099926 0;
BA_ "GenMsgRequestable" BO_ 2552099926 0;
BA_ "GenMsgSendType" BO_ 2552099926 0;
BA_ "GenMsgCycleTime" BO_ 2552099926 250;
BA_ "GenMsgILSupport" BO_ 2551994100 0;
BA_ "GenMsgRequestable" BO_ 2551994100 0;
BA_ "GenMsgSendType" BO_ 2551994100 0;
BA_ "GenMsgCycleTime" BO_ 2551994100 250;
BA_ "GenMsgILSupport" BO_ 2417685590 0;
BA_ "GenMsgRequestable" BO_ 2417685590 0;
BA_ "GenMsgSendType" BO_ 2417685590 0;
BA_ "GenMsgCycleTime" BO_ 2417685590 10;
BA_ "GenMsgILSupport" BO_ 2417579764 0;
BA_ "GenMsgRequestable" BO_ 2417579764 0;
BA_ "GenMsgSendType" BO_ 2417579764 0;
BA_ "GenMsgCycleTime" BO_ 2417579764 10;
BA_ "TpJ1939VarDlc" BO_ 2618775284 1;
BA_ "GenMsgILSupport" BO_ 2618775284 0;
BA_ "GenMsgRequestable" BO_ 2618775284 0;
BA_ "GenMsgSendType" BO_ 2618775284 0;
BA_ "GenMsgCycleTime" BO_ 2618775284 10000;
BA_ "TpJ1939VarDlc" BO_ 2618709748 1;
BA_ "GenMsgILSupport" BO_ 2618709748 0;
BA_ "GenMsgRequestable" BO_ 2618709748 0;
BA_ "GenMsgSendType" BO_ 2618709748 0;
BA_ "GenMsgCycleTime" BO_ 2618709748 10000;
BA_ "SigType" SG_ 2283795542 Timeout_BSD 4;
BA_ "GenSigILSupport" SG_ 2283795542 Timeout_BSD 0;
BA_ "SPN" SG_ 2283795542 Timeout_BSD 3922;
BA_ "SigType" SG_ 2283795542 Timeout_BST 4;
BA_ "GenSigILSupport" SG_ 2283795542 Timeout_BST 0;
BA_ "SPN" SG_ 2283795542 Timeout_BST 3926;
BA_ "SigType" SG_ 2283795542 Timeout_BSM 4;
BA_ "GenSigILSupport" SG_ 2283795542 Timeout_BSM 0;
BA_ "SPN" SG_ 2283795542 Timeout_BSM 3925;
BA_ "SigType" SG_ 2283795542 Timeout_BCS 4;
BA_ "GenSigILSupport" SG_ 2283795542 Timeout_BCS 0;
BA_ "SPN" SG_ 2283795542 Timeout_BCS 3924;
BA_ "SigType" SG_ 2283795542 Timeout_BRO 4;
BA_ "GenSigILSupport" SG_ 2283795542 Timeout_BRO 0;
BA_ "SPN" SG_ 2283795542 Timeout_BRO 3923;
BA_ "SigType" SG_ 2283795542 Timeout_BCP 4;
BA_ "GenSigILSupport" SG_ 2283795542 Timeout_BCP 0;
BA_ "SPN" SG_ 2283795542 Timeout_BCP 3922;
BA_ "SigType" SG_ 2283795542 Timeout_BRM 4;
BA_ "GenSigILSupport" SG_ 2283795542 Timeout_BRM 0;
BA_ "SPN" SG_ 2283795542 Timeout_BRM 3921;
BA_ "SigType" SG_ 2283689716 Timeout_CSD 4;
BA_ "GenSigILSupport" SG_ 2283689716 Timeout_CSD 0;
BA_ "SPN" SG_ 2283689716 Timeout_CSD 3907;
BA_ "SigType" SG_ 2283689716 Timeout_CST 4;
BA_ "GenSigILSupport" SG_ 2283689716 Timeout_CST 0;
BA_ "SPN" SG_ 2283689716 Timeout_CST 3906;
BA_ "SigType" SG_ 2283689716 Timeout_CCS 4;
BA_ "GenSigILSupport" SG_ 2283689716 Timeout_CCS 0;
BA_ "SPN" SG_ 2283689716 Timeout_CCS 3905;
BA_ "SigType" SG_ 2283689716 Timeout_CRO 4;
BA_ "GenSigILSupport" SG_ 2283689716 Timeout_CRO 0;
BA_ "SPN" SG_ 2283689716 Timeout_CRO 3904;
BA_ "SigType" SG_ 2283689716 Timeout_CTS_CML 4;
BA_ "GenSigILSupport" SG_ 2283689716 Timeout_CTS_CML 0;
BA_ "SPN" SG_ 2283689716 Timeout_CTS_CML 3903;
BA_ "SigType" SG_ 2283689716 Timeout_CRM_Recognized 4;
BA_ "GenSigILSupport" SG_ 2283689716 Timeout_CRM_Recognized 0;
BA_ "SPN" SG_ 2283689716 Timeout_CRM_Recognized 3902;
BA_ "SigType" SG_ 2283689716 Timeout_CRM_Unrecognized 4;
BA_ "GenSigILSupport" SG_ 2283689716 Timeout_CRM_Unrecognized 0;
BA_ "SPN" SG_ 2283689716 Timeout_CRM_Unrecognized 3901;
BA_ "SigType" SG_ 2552099926 ChargerNo 1;
BA_ "GenSigILSupport" SG_ 2552099926 ChargerNo 0;
BA_ "SPN" SG_ 2552099926 ChargerNo 3613;
BA_ "SigType" SG_ 2552099926 OutputEnergy 1;
BA_ "GenSigILSupport" SG_ 2552099926 OutputEnergy 0;
BA_ "SPN" SG_ 2552099926 OutputEnergy 3612;
BA_ "SigType" SG_ 2552099926 CumulativeChargingTime 1;
BA_ "GenSigILSupport" SG_ 2552099926 CumulativeChargingTime 0;
BA_ "SPN" SG_ 2552099926 CumulativeChargingTime 3611;
BA_ "SPN" SG_ 2551994100 SingleBatteryMaxTemperature 3605;
BA_ "GenSigILSupport" SG_ 2551994100 SingleBatteryMaxTemperature 0;
BA_ "GenSigStartValue" SG_ 2551994100 SingleBatteryMaxTemperature 50;
BA_ "SigType" SG_ 2551994100 SingleBatteryMaxTemperature 1;
BA_ "SPN" SG_ 2551994100 SingleBatteryMinTemperature 3604;
BA_ "GenSigILSupport" SG_ 2551994100 SingleBatteryMinTemperature 0;
BA_ "GenSigStartValue" SG_ 2551994100 SingleBatteryMinTemperature 50;
BA_ "SigType" SG_ 2551994100 SingleBatteryMinTemperature 1;
BA_ "SPN" SG_ 2551994100 SingleBatteryMaxVoltage 3603;
BA_ "GenSigILSupport" SG_ 2551994100 SingleBatteryMaxVoltage 0;
BA_ "SigType" SG_ 2551994100 SingleBatteryMaxVoltage 1;
BA_ "SPN" SG_ 2551994100 SingleBatteryMinVoltage 3602;
BA_ "GenSigILSupport" SG_ 2551994100 SingleBatteryMinVoltage 0;
BA_ "SigType" SG_ 2551994100 SingleBatteryMinVoltage 1;
BA_ "SigType" SG_ 2551994100 SuspendStateOfChargeSOC 1;
BA_ "GenSigILSupport" SG_ 2551994100 SuspendStateOfChargeSOC 0;
BA_ "SPN" SG_ 2551994100 SuspendStateOfChargeSOC 3601;
BA_ "SigType" SG_ 2417685590 CrgSuspError_AbnormalVoltage 4;
BA_ "GenSigILSupport" SG_ 2417685590 CrgSuspError_AbnormalVoltage 0;
BA_ "SPN" SG_ 2417685590 CrgSuspError_AbnormalVoltage 3523;
BA_ "SigType" SG_ 2417685590 CrgSuspError_CurrentMismatch 4;
BA_ "GenSigILSupport" SG_ 2417685590 CrgSuspError_CurrentMismatch 0;
BA_ "SPN" SG_ 2417685590 CrgSuspError_CurrentMismatch 3523;
BA_ "SigType" SG_ 2417685590 CrgSuspFault_OtherFault 4;
BA_ "GenSigILSupport" SG_ 2417685590 CrgSuspFault_OtherFault 0;
BA_ "SPN" SG_ 2417685590 CrgSuspFault_OtherFault 3522;
BA_ "SigType" SG_ 2417685590 CrgSuspFault_SuddenStop 4;
BA_ "GenSigILSupport" SG_ 2417685590 CrgSuspFault_SuddenStop 0;
BA_ "SPN" SG_ 2417685590 CrgSuspFault_SuddenStop 3522;
BA_ "SigType" SG_ 2417685590 CrgSuspFault_CannotSupply 4;
BA_ "GenSigILSupport" SG_ 2417685590 CrgSuspFault_CannotSupply 0;
BA_ "SPN" SG_ 2417685590 CrgSuspFault_CannotSupply 3522;
BA_ "SigType" SG_ 2417685590 CrgSuspFault_CrgTempInt 4;
BA_ "GenSigILSupport" SG_ 2417685590 CrgSuspFault_CrgTempInt 0;
BA_ "SPN" SG_ 2417685590 CrgSuspFault_CrgTempInt 3522;
BA_ "SigType" SG_ 2417685590 CrgSuspFault_ChargeConn 4;
BA_ "GenSigILSupport" SG_ 2417685590 CrgSuspFault_ChargeConn 0;
BA_ "SPN" SG_ 2417685590 CrgSuspFault_ChargeConn 3522;
BA_ "SigType" SG_ 2417685590 CrgSuspFault_CrgTemp 4;
BA_ "GenSigILSupport" SG_ 2417685590 CrgSuspFault_CrgTemp 0;
BA_ "SPN" SG_ 2417685590 CrgSuspFault_CrgTemp 3522;
BA_ "SigType" SG_ 2417685590 CrgSuspCause_BmsActiveSusp 4;
BA_ "GenSigILSupport" SG_ 2417685590 CrgSuspCause_BmsActiveSusp 0;
BA_ "SPN" SG_ 2417685590 CrgSuspCause_BmsActiveSusp 3521;
BA_ "SigType" SG_ 2417685590 CrgSuspCause_Fault 4;
BA_ "GenSigILSupport" SG_ 2417685590 CrgSuspCause_Fault 0;
BA_ "SPN" SG_ 2417685590 CrgSuspCause_Fault 3521;
BA_ "SigType" SG_ 2417685590 CrgSuspCause_Artificial 4;
BA_ "GenSigILSupport" SG_ 2417685590 CrgSuspCause_Artificial 0;
BA_ "SPN" SG_ 2417685590 CrgSuspCause_Artificial 3521;
BA_ "GenSigILSupport" SG_ 2417685590 CrgSuspCause_ChargerCond 0;
BA_ "SPN" SG_ 2417685590 CrgSuspCause_ChargerCond 3521;
BA_ "SigType" SG_ 2417685590 CrgSuspCause_ChargerCond 4;
BA_ "SPN" SG_ 2417579764 BmsSuspError_AbnormalVoltage 3513;
BA_ "GenSigILSupport" SG_ 2417579764 BmsSuspError_AbnormalVoltage 0;
BA_ "SigType" SG_ 2417579764 BmsSuspError_AbnormalVoltage 4;
BA_ "SPN" SG_ 2417579764 BmsSuspError_ExcessiveCurrent 3513;
BA_ "GenSigILSupport" SG_ 2417579764 BmsSuspError_ExcessiveCurrent 0;
BA_ "SigType" SG_ 2417579764 BmsSuspError_ExcessiveCurrent 4;
BA_ "SigType" SG_ 2417579764 BmsSuspFault_OtherFaults 4;
BA_ "GenSigILSupport" SG_ 2417579764 BmsSuspFault_OtherFaults 0;
BA_ "SPN" SG_ 2417579764 BmsSuspFault_OtherFaults 3512;
BA_ "SigType" SG_ 2417579764 BmsSuspFault_BmsTemp 4;
BA_ "GenSigILSupport" SG_ 2417579764 BmsSuspFault_BmsTemp 0;
BA_ "SPN" SG_ 2417579764 BmsSuspFault_BmsTemp 3512;
BA_ "SigType" SG_ 2417579764 BmsSuspFault_VoltageDetection 4;
BA_ "GenSigILSupport" SG_ 2417579764 BmsSuspFault_VoltageDetection 0;
BA_ "SPN" SG_ 2417579764 BmsSuspFault_VoltageDetection 3512;
BA_ "SigType" SG_ 2417579764 BmsSuspFault_VoltageRelay 4;
BA_ "GenSigILSupport" SG_ 2417579764 BmsSuspFault_VoltageRelay 0;
BA_ "SPN" SG_ 2417579764 BmsSuspFault_VoltageRelay 3512;
BA_ "SigType" SG_ 2417579764 BmsSuspFault_BatteryTemp 4;
BA_ "GenSigILSupport" SG_ 2417579764 BmsSuspFault_BatteryTemp 0;
BA_ "SPN" SG_ 2417579764 BmsSuspFault_BatteryTemp 3512;
BA_ "SigType" SG_ 2417579764 BmsSuspFault_ChargeConn 4;
BA_ "GenSigILSupport" SG_ 2417579764 BmsSuspFault_ChargeConn 0;
BA_ "SPN" SG_ 2417579764 BmsSuspFault_ChargeConn 3512;
BA_ "SigType" SG_ 2417579764 BmsSuspFault_OutputConnTemp 4;
BA_ "GenSigILSupport" SG_ 2417579764 BmsSuspFault_OutputConnTemp 0;
BA_ "SPN" SG_ 2417579764 BmsSuspFault_OutputConnTemp 3512;
BA_ "SigType" SG_ 2417579764 BmsSuspFault_Insulation 4;
BA_ "GenSigILSupport" SG_ 2417579764 BmsSuspFault_Insulation 0;
BA_ "SPN" SG_ 2417579764 BmsSuspFault_Insulation 3512;
BA_ "GenSigILSupport" SG_ 2417579764 BmsSuspCause_ActiveSuspend 0;
BA_ "SPN" SG_ 2417579764 BmsSuspCause_ActiveSuspend 3511;
BA_ "SigType" SG_ 2417579764 BmsSuspCause_ActiveSuspend 4;
BA_ "GenSigILSupport" SG_ 2417579764 BmsSuspCause_SingleVoltage 0;
BA_ "SPN" SG_ 2417579764 BmsSuspCause_SingleVoltage 3511;
BA_ "SigType" SG_ 2417579764 BmsSuspCause_SingleVoltage 4;
BA_ "GenSigILSupport" SG_ 2417579764 BmsSuspCause_TotalVoltage 0;
BA_ "SPN" SG_ 2417579764 BmsSuspCause_TotalVoltage 3511;
BA_ "SigType" SG_ 2417579764 BmsSuspCause_TotalVoltage 4;
BA_ "GenSigILSupport" SG_ 2417579764 BmsSuspCause_SOC 0;
BA_ "SPN" SG_ 2417579764 BmsSuspCause_SOC 3511;
BA_ "SigType" SG_ 2417579764 BmsSuspCause_SOC 4;
BA_ "SPN" SG_ 2618775284 BatteryReserved16 3506;
BA_ "GenSigILSupport" SG_ 2618775284 BatteryReserved16 0;
BA_ "SPN" SG_ 2618775284 BatteryReserved15 3505;
BA_ "GenSigILSupport" SG_ 2618775284 BatteryReserved15 0;
BA_ "SPN" SG_ 2618775284 BatteryReserved14 3504;
BA_ "GenSigILSupport" SG_ 2618775284 BatteryReserved14 0;
BA_ "SPN" SG_ 2618775284 BatteryReserved13 3503;
BA_ "GenSigILSupport" SG_ 2618775284 BatteryReserved13 0;
BA_ "SPN" SG_ 2618775284 BatteryReserved12 3502;
BA_ "GenSigILSupport" SG_ 2618775284 BatteryReserved12 0;
BA_ "SPN" SG_ 2618775284 BatteryReserved11 3501;
BA_ "GenSigILSupport" SG_ 2618775284 BatteryReserved11 0;
BA_ "SPN" SG_ 2618775284 BatteryReserved10 3500;
BA_ "GenSigILSupport" SG_ 2618775284 BatteryReserved10 0;
BA_ "SPN" SG_ 2618775284 BatteryReserved09 3499;
BA_ "GenSigILSupport" SG_ 2618775284 BatteryReserved09 0;
BA_ "SPN" SG_ 2618775284 BatteryReserved08 3498;
BA_ "GenSigILSupport" SG_ 2618775284 BatteryReserved08 0;
BA_ "SPN" SG_ 2618775284 BatteryReserved07 3497;
BA_ "GenSigILSupport" SG_ 2618775284 BatteryReserved07 0;
BA_ "SPN" SG_ 2618775284 BatteryReserved06 3496;
BA_ "GenSigILSupport" SG_ 2618775284 BatteryReserved06 0;
BA_ "SPN" SG_ 2618775284 BatteryReserved05 3495;
BA_ "GenSigILSupport" SG_ 2618775284 BatteryReserved05 0;
BA_ "SPN" SG_ 2618775284 BatteryReserved04 3494;
BA_ "GenSigILSupport" SG_ 2618775284 BatteryReserved04 0;
BA_ "SPN" SG_ 2618775284 BatteryReserved03 3493;
BA_ "GenSigILSupport" SG_ 2618775284 BatteryReserved03 0;
BA_ "SPN" SG_ 2618775284 BatteryReserved02 3492;
BA_ "GenSigILSupport" SG_ 2618775284 BatteryReserved02 0;
BA_ "GenSigILSupport" SG_ 2618775284 BatteryReserved01 0;
BA_ "SPN" SG_ 2618775284 BatteryReserved01 3491;
BA_ "SigType" SG_ 2618709748 BatteryTemperature128 1;
BA_ "GenSigStartValue" SG_ 2618709748 BatteryTemperature128 50;
BA_ "GenSigILSupport" SG_ 2618709748 BatteryTemperature128 0;
BA_ "SPN" SG_ 2618709748 BatteryTemperature128 3488;
BA_ "SigType" SG_ 2618709748 BatteryTemperature127 1;
BA_ "GenSigStartValue" SG_ 2618709748 BatteryTemperature127 50;
BA_ "GenSigILSupport" SG_ 2618709748 BatteryTemperature127 0;
BA_ "SPN" SG_ 2618709748 BatteryTemperature127 3487;
BA_ "SigType" SG_ 2618709748 BatteryTemperature126 1;
BA_ "GenSigStartValue" SG_ 2618709748 BatteryTemperature126 50;
BA_ "GenSigILSupport" SG_ 2618709748 BatteryTemperature126 0;
BA_ "SPN" SG_ 2618709748 BatteryTemperature126 3486;
BA_ "SigType" SG_ 2618709748 BatteryTemperature125 1;
BA_ "GenSigStartValue" SG_ 2618709748 BatteryTemperature125 50;
BA_ "GenSigILSupport" SG_ 2618709748 BatteryTemperature125 0;
BA_ "SPN" SG_ 2618709748 BatteryTemperature125 3485;
BA_ "SigType" SG_ 2618709748 BatteryTemperature124 1;
BA_ "GenSigStartValue" SG_ 2618709748 BatteryTemperature124 50;
BA_ "GenSigILSupport" SG_ 2618709748 BatteryTemperature124 0;
BA_ "SPN" SG_ 2618709748 BatteryTemperature124 3484;
BA_ "SigType" SG_ 2618709748 BatteryTemperature123 1;
BA_ "GenSigStartValue" SG_ 2618709748 BatteryTemperature123 50;
BA_ "GenSigILSupport" SG_ 2618709748 BatteryTemperature123 0;
BA_ "SPN" SG_ 2618709748 BatteryTemperature123 3483;
BA_ "SigType" SG_ 2618709748 BatteryTemperature122 1;
BA_ "GenSigStartValue" SG_ 2618709748 BatteryTemperature122 50;
BA_ "GenSigILSupport" SG_ 2618709748 BatteryTemperature122 0;
BA_ "SPN" SG_ 2618709748 BatteryTemperature122 3482;
BA_ "SigType" SG_ 2618709748 BatteryTemperature121 1;
BA_ "GenSigStartValue" SG_ 2618709748 BatteryTemperature121 50;
BA_ "GenSigILSupport" SG_ 2618709748 BatteryTemperature121 0;
BA_ "SPN" SG_ 2618709748 BatteryTemperature121 3481;
BA_ "SigType" SG_ 2618709748 BatteryTemperature120 1;
BA_ "GenSigStartValue" SG_ 2618709748 BatteryTemperature120 50;
BA_ "GenSigILSupport" SG_ 2618709748 BatteryTemperature120 0;
BA_ "SPN" SG_ 2618709748 BatteryTemperature120 3480;
BA_ "SigType" SG_ 2618709748 BatteryTemperature119 1;
BA_ "GenSigStartValue" SG_ 2618709748 BatteryTemperature119 50;
BA_ "GenSigILSupport" SG_ 2618709748 BatteryTemperature119 0;
BA_ "SPN" SG_ 2618709748 BatteryTemperature119 3479;
BA_ "SigType" SG_ 2618709748 BatteryTemperature118 1;
BA_ "GenSigStartValue" SG_ 2618709748 BatteryTemperature118 50;
BA_ "GenSigILSupport" SG_ 2618709748 BatteryTemperature118 0;
BA_ "SPN" SG_ 2618709748 BatteryTemperature118 3478;
BA_ "SigType" SG_ 2618709748 BatteryTemperature117 1;
BA_ "GenSigStartValue" SG_ 2618709748 BatteryTemperature117 50;
BA_ "GenSigILSupport" SG_ 2618709748 BatteryTemperature117 0;
BA_ "SPN" SG_ 2618709748 BatteryTemperature117 3477;
BA_ "SigType" SG_ 2618709748 BatteryTemperature116 1;
BA_ "GenSigStartValue" SG_ 2618709748 BatteryTemperature116 50;
BA_ "GenSigILSupport" SG_ 2618709748 BatteryTemperature116 0;
BA_ "SPN" SG_ 2618709748 BatteryTemperature116 3476;
BA_ "SigType" SG_ 2618709748 BatteryTemperature115 1;
BA_ "GenSigStartValue" SG_ 2618709748 BatteryTemperature115 50;
BA_ "GenSigILSupport" SG_ 2618709748 BatteryTemperature115 0;
BA_ "SPN" SG_ 2618709748 BatteryTemperature115 3475;
BA_ "SigType" SG_ 2618709748 BatteryTemperature114 1;
BA_ "GenSigStartValue" SG_ 2618709748 BatteryTemperature114 50;
BA_ "GenSigILSupport" SG_ 2618709748 BatteryTemperature114 0;
BA_ "SPN" SG_ 2618709748 BatteryTemperature114 3474;
BA_ "SigType" SG_ 2618709748 BatteryTemperature113 1;
BA_ "GenSigStartValue" SG_ 2618709748 BatteryTemperature113 50;
BA_ "GenSigILSupport" SG_ 2618709748 BatteryTemperature113 0;
BA_ "SPN" SG_ 2618709748 BatteryTemperature113 3473;
BA_ "SigType" SG_ 2618709748 BatteryTemperature112 1;
BA_ "GenSigStartValue" SG_ 2618709748 BatteryTemperature112 50;
BA_ "GenSigILSupport" SG_ 2618709748 BatteryTemperature112 0;
BA_ "SPN" SG_ 2618709748 BatteryTemperature112 3472;
BA_ "SigType" SG_ 2618709748 BatteryTemperature111 1;
BA_ "GenSigStartValue" SG_ 2618709748 BatteryTemperature111 50;
BA_ "GenSigILSupport" SG_ 2618709748 BatteryTemperature111 0;
BA_ "SPN" SG_ 2618709748 BatteryTemperature111 3471;
BA_ "SigType" SG_ 2618709748 BatteryTemperature110 1;
BA_ "GenSigStartValue" SG_ 2618709748 BatteryTemperature110 50;
BA_ "GenSigILSupport" SG_ 2618709748 BatteryTemperature110 0;
BA_ "SPN" SG_ 2618709748 BatteryTemperature110 3470;
BA_ "SigType" SG_ 2618709748 BatteryTemperature109 1;
BA_ "GenSigStartValue" SG_ 2618709748 BatteryTemperature109 50;
BA_ "GenSigILSupport" SG_ 2618709748 BatteryTemperature109 0;
BA_ "SPN" SG_ 2618709748 BatteryTemperature109 3469;
BA_ "SigType" SG_ 2618709748 BatteryTemperature108 1;
BA_ "GenSigStartValue" SG_ 2618709748 BatteryTemperature108 50;
BA_ "GenSigILSupport" SG_ 2618709748 BatteryTemperature108 0;
BA_ "SPN" SG_ 2618709748 BatteryTemperature108 3468;
BA_ "SigType" SG_ 2618709748 BatteryTemperature107 1;
BA_ "GenSigStartValue" SG_ 2618709748 BatteryTemperature107 50;
BA_ "GenSigILSupport" SG_ 2618709748 BatteryTemperature107 0;
BA_ "SPN" SG_ 2618709748 BatteryTemperature107 3467;
BA_ "SigType" SG_ 2618709748 BatteryTemperature106 1;
BA_ "GenSigStartValue" SG_ 2618709748 BatteryTemperature106 50;
BA_ "GenSigILSupport" SG_ 2618709748 BatteryTemperature106 0;
BA_ "SPN" SG_ 2618709748 BatteryTemperature106 3466;
BA_ "SigType" SG_ 2618709748 BatteryTemperature105 1;
BA_ "GenSigStartValue" SG_ 2618709748 BatteryTemperature105 50;
BA_ "GenSigILSupport" SG_ 2618709748 BatteryTemperature105 0;
BA_ "SPN" SG_ 2618709748 BatteryTemperature105 3465;
BA_ "SigType" SG_ 2618709748 BatteryTemperature104 1;
BA_ "GenSigStartValue" SG_ 2618709748 BatteryTemperature104 50;
BA_ "GenSigILSupport" SG_ 2618709748 BatteryTemperature104 0;
BA_ "SPN" SG_ 2618709748 BatteryTemperature104 3464;
BA_ "SigType" SG_ 2618709748 BatteryTemperature103 1;
BA_ "GenSigStartValue" SG_ 2618709748 BatteryTemperature103 50;
BA_ "GenSigILSupport" SG_ 2618709748 BatteryTemperature103 0;
BA_ "SPN" SG_ 2618709748 BatteryTemperature103 3463;
BA_ "SigType" SG_ 2618709748 BatteryTemperature102 1;
BA_ "GenSigStartValue" SG_ 2618709748 BatteryTemperature102 50;
BA_ "GenSigILSupport" SG_ 2618709748 BatteryTemperature102 0;
BA_ "SPN" SG_ 2618709748 BatteryTemperature102 3462;
BA_ "SigType" SG_ 2618709748 BatteryTemperature101 1;
BA_ "GenSigStartValue" SG_ 2618709748 BatteryTemperature101 50;
BA_ "GenSigILSupport" SG_ 2618709748 BatteryTemperature101 0;
BA_ "SPN" SG_ 2618709748 BatteryTemperature101 3461;
BA_ "SigType" SG_ 2618709748 BatteryTemperature100 1;
BA_ "GenSigStartValue" SG_ 2618709748 BatteryTemperature100 50;
BA_ "GenSigILSupport" SG_ 2618709748 BatteryTemperature100 0;
BA_ "SPN" SG_ 2618709748 BatteryTemperature100 3460;
BA_ "SigType" SG_ 2618709748 BatteryTemperature099 1;
BA_ "GenSigStartValue" SG_ 2618709748 BatteryTemperature099 50;
BA_ "GenSigILSupport" SG_ 2618709748 BatteryTemperature099 0;
BA_ "SPN" SG_ 2618709748 BatteryTemperature099 3459;
BA_ "SigType" SG_ 2618709748 BatteryTemperature098 1;
BA_ "GenSigStartValue" SG_ 2618709748 BatteryTemperature098 50;
BA_ "GenSigILSupport" SG_ 2618709748 BatteryTemperature098 0;
BA_ "SPN" SG_ 2618709748 BatteryTemperature098 3458;
BA_ "SigType" SG_ 2618709748 BatteryTemperature097 1;
BA_ "GenSigStartValue" SG_ 2618709748 BatteryTemperature097 50;
BA_ "GenSigILSupport" SG_ 2618709748 BatteryTemperature097 0;
BA_ "SPN" SG_ 2618709748 BatteryTemperature097 3457;
BA_ "SigType" SG_ 2618709748 BatteryTemperature096 1;
BA_ "GenSigStartValue" SG_ 2618709748 BatteryTemperature096 50;
BA_ "GenSigILSupport" SG_ 2618709748 BatteryTemperature096 0;
BA_ "SPN" SG_ 2618709748 BatteryTemperature096 3456;
BA_ "SigType" SG_ 2618709748 BatteryTemperature095 1;
BA_ "GenSigStartValue" SG_ 2618709748 BatteryTemperature095 50;
BA_ "GenSigILSupport" SG_ 2618709748 BatteryTemperature095 0;
BA_ "SPN" SG_ 2618709748 BatteryTemperature095 3455;
BA_ "SigType" SG_ 2618709748 BatteryTemperature094 1;
BA_ "GenSigStartValue" SG_ 2618709748 BatteryTemperature094 50;
BA_ "GenSigILSupport" SG_ 2618709748 BatteryTemperature094 0;
BA_ "SPN" SG_ 2618709748 BatteryTemperature094 3454;
BA_ "SigType" SG_ 2618709748 BatteryTemperature093 1;
BA_ "GenSigStartValue" SG_ 2618709748 BatteryTemperature093 50;
BA_ "GenSigILSupport" SG_ 2618709748 BatteryTemperature093 0;
BA_ "SPN" SG_ 2618709748 BatteryTemperature093 3453;
BA_ "SigType" SG_ 2618709748 BatteryTemperature092 1;
BA_ "GenSigStartValue" SG_ 2618709748 BatteryTemperature092 50;
BA_ "GenSigILSupport" SG_ 2618709748 BatteryTemperature092 0;
BA_ "SPN" SG_ 2618709748 BatteryTemperature092 3452;
BA_ "SigType" SG_ 2618709748 BatteryTemperature091 1;
BA_ "GenSigStartValue" SG_ 2618709748 BatteryTemperature091 50;
BA_ "GenSigILSupport" SG_ 2618709748 BatteryTemperature091 0;
BA_ "SPN" SG_ 2618709748 BatteryTemperature091 3451;
BA_ "SigType" SG_ 2618709748 BatteryTemperature090 1;
BA_ "GenSigStartValue" SG_ 2618709748 BatteryTemperature090 50;
BA_ "GenSigILSupport" SG_ 2618709748 BatteryTemperature090 0;
BA_ "SPN" SG_ 2618709748 BatteryTemperature090 3450;
BA_ "SigType" SG_ 2618709748 BatteryTemperature089 1;
BA_ "GenSigStartValue" SG_ 2618709748 BatteryTemperature089 50;
BA_ "GenSigILSupport" SG_ 2618709748 BatteryTemperature089 0;
BA_ "SPN" SG_ 2618709748 BatteryTemperature089 3449;
BA_ "SigType" SG_ 2618709748 BatteryTemperature088 1;
BA_ "GenSigStartValue" SG_ 2618709748 BatteryTemperature088 50;
BA_ "GenSigILSupport" SG_ 2618709748 BatteryTemperature088 0;
BA_ "SPN" SG_ 2618709748 BatteryTemperature088 3448;
BA_ "SigType" SG_ 2618709748 BatteryTemperature087 1;
BA_ "GenSigStartValue" SG_ 2618709748 BatteryTemperature087 50;
BA_ "GenSigILSupport" SG_ 2618709748 BatteryTemperature087 0;
BA_ "SPN" SG_ 2618709748 BatteryTemperature087 3447;
BA_ "SigType" SG_ 2618709748 BatteryTemperature086 1;
BA_ "GenSigStartValue" SG_ 2618709748 BatteryTemperature086 50;
BA_ "GenSigILSupport" SG_ 2618709748 BatteryTemperature086 0;
BA_ "SPN" SG_ 2618709748 BatteryTemperature086 3446;
BA_ "SigType" SG_ 2618709748 BatteryTemperature085 1;
BA_ "GenSigStartValue" SG_ 2618709748 BatteryTemperature085 50;
BA_ "GenSigILSupport" SG_ 2618709748 BatteryTemperature085 0;
BA_ "SPN" SG_ 2618709748 BatteryTemperature085 3445;
BA_ "SigType" SG_ 2618709748 BatteryTemperature084 1;
BA_ "GenSigStartValue" SG_ 2618709748 BatteryTemperature084 50;
BA_ "GenSigILSupport" SG_ 2618709748 BatteryTemperature084 0;
BA_ "SPN" SG_ 2618709748 BatteryTemperature084 3444;
BA_ "SigType" SG_ 2618709748 BatteryTemperature083 1;
BA_ "GenSigStartValue" SG_ 2618709748 BatteryTemperature083 50;
BA_ "GenSigILSupport" SG_ 2618709748 BatteryTemperature083 0;
BA_ "SPN" SG_ 2618709748 BatteryTemperature083 3443;
BA_ "SigType" SG_ 2618709748 BatteryTemperature082 1;
BA_ "GenSigStartValue" SG_ 2618709748 BatteryTemperature082 50;
BA_ "GenSigILSupport" SG_ 2618709748 BatteryTemperature082 0;
BA_ "SPN" SG_ 2618709748 BatteryTemperature082 3442;
BA_ "SigType" SG_ 2618709748 BatteryTemperature081 1;
BA_ "GenSigStartValue" SG_ 2618709748 BatteryTemperature081 50;
BA_ "GenSigILSupport" SG_ 2618709748 BatteryTemperature081 0;
BA_ "SPN" SG_ 2618709748 BatteryTemperature081 3441;
BA_ "SigType" SG_ 2618709748 BatteryTemperature080 1;
BA_ "GenSigStartValue" SG_ 2618709748 BatteryTemperature080 50;
BA_ "GenSigILSupport" SG_ 2618709748 BatteryTemperature080 0;
BA_ "SPN" SG_ 2618709748 BatteryTemperature080 3440;
BA_ "SigType" SG_ 2618709748 BatteryTemperature079 1;
BA_ "GenSigStartValue" SG_ 2618709748 BatteryTemperature079 50;
BA_ "GenSigILSupport" SG_ 2618709748 BatteryTemperature079 0;
BA_ "SPN" SG_ 2618709748 BatteryTemperature079 3439;
BA_ "SigType" SG_ 2618709748 BatteryTemperature078 1;
BA_ "GenSigStartValue" SG_ 2618709748 BatteryTemperature078 50;
BA_ "GenSigILSupport" SG_ 2618709748 BatteryTemperature078 0;
BA_ "SPN" SG_ 2618709748 BatteryTemperature078 3438;
BA_ "SigType" SG_ 2618709748 BatteryTemperature077 1;
BA_ "GenSigStartValue" SG_ 2618709748 BatteryTemperature077 50;
BA_ "GenSigILSupport" SG_ 2618709748 BatteryTemperature077 0;
BA_ "SPN" SG_ 2618709748 BatteryTemperature077 3437;
BA_ "SigType" SG_ 2618709748 BatteryTemperature076 1;
BA_ "GenSigStartValue" SG_ 2618709748 BatteryTemperature076 50;
BA_ "GenSigILSupport" SG_ 2618709748 BatteryTemperature076 0;
BA_ "SPN" SG_ 2618709748 BatteryTemperature076 3436;
BA_ "SigType" SG_ 2618709748 BatteryTemperature075 1;
BA_ "GenSigStartValue" SG_ 2618709748 BatteryTemperature075 50;
BA_ "GenSigILSupport" SG_ 2618709748 BatteryTemperature075 0;
BA_ "SPN" SG_ 2618709748 BatteryTemperature075 3435;
BA_ "SigType" SG_ 2618709748 BatteryTemperature074 1;
BA_ "GenSigStartValue" SG_ 2618709748 BatteryTemperature074 50;
BA_ "GenSigILSupport" SG_ 2618709748 BatteryTemperature074 0;
BA_ "SPN" SG_ 2618709748 BatteryTemperature074 3434;
BA_ "SigType" SG_ 2618709748 BatteryTemperature073 1;
BA_ "GenSigStartValue" SG_ 2618709748 BatteryTemperature073 50;
BA_ "GenSigILSupport" SG_ 2618709748 BatteryTemperature073 0;
BA_ "SPN" SG_ 2618709748 BatteryTemperature073 3433;
BA_ "SigType" SG_ 2618709748 BatteryTemperature072 1;
BA_ "GenSigStartValue" SG_ 2618709748 BatteryTemperature072 50;
BA_ "GenSigILSupport" SG_ 2618709748 BatteryTemperature072 0;
BA_ "SPN" SG_ 2618709748 BatteryTemperature072 3432;
BA_ "SigType" SG_ 2618709748 BatteryTemperature071 1;
BA_ "GenSigStartValue" SG_ 2618709748 BatteryTemperature071 50;
BA_ "GenSigILSupport" SG_ 2618709748 BatteryTemperature071 0;
BA_ "SPN" SG_ 2618709748 BatteryTemperature071 3431;
BA_ "SigType" SG_ 2618709748 BatteryTemperature070 1;
BA_ "GenSigStartValue" SG_ 2618709748 BatteryTemperature070 50;
BA_ "GenSigILSupport" SG_ 2618709748 BatteryTemperature070 0;
BA_ "SPN" SG_ 2618709748 BatteryTemperature070 3430;
BA_ "SigType" SG_ 2618709748 BatteryTemperature069 1;
BA_ "GenSigStartValue" SG_ 2618709748 BatteryTemperature069 50;
BA_ "GenSigILSupport" SG_ 2618709748 BatteryTemperature069 0;
BA_ "SPN" SG_ 2618709748 BatteryTemperature069 3429;
BA_ "SigType" SG_ 2618709748 BatteryTemperature068 1;
BA_ "GenSigStartValue" SG_ 2618709748 BatteryTemperature068 50;
BA_ "GenSigILSupport" SG_ 2618709748 BatteryTemperature068 0;
BA_ "SPN" SG_ 2618709748 BatteryTemperature068 3428;
BA_ "SigType" SG_ 2618709748 BatteryTemperature067 1;
BA_ "GenSigStartValue" SG_ 2618709748 BatteryTemperature067 50;
BA_ "GenSigILSupport" SG_ 2618709748 BatteryTemperature067 0;
BA_ "SPN" SG_ 2618709748 BatteryTemperature067 3427;
BA_ "SigType" SG_ 2618709748 BatteryTemperature066 1;
BA_ "GenSigStartValue" SG_ 2618709748 BatteryTemperature066 50;
BA_ "GenSigILSupport" SG_ 2618709748 BatteryTemperature066 0;
BA_ "SPN" SG_ 2618709748 BatteryTemperature066 3426;
BA_ "SigType" SG_ 2618709748 BatteryTemperature065 1;
BA_ "GenSigStartValue" SG_ 2618709748 BatteryTemperature065 50;
BA_ "GenSigILSupport" SG_ 2618709748 BatteryTemperature065 0;
BA_ "SPN" SG_ 2618709748 BatteryTemperature065 3425;
BA_ "SigType" SG_ 2618709748 BatteryTemperature064 1;
BA_ "GenSigStartValue" SG_ 2618709748 BatteryTemperature064 50;
BA_ "GenSigILSupport" SG_ 2618709748 BatteryTemperature064 0;
BA_ "SPN" SG_ 2618709748 BatteryTemperature064 3424;
BA_ "SigType" SG_ 2618709748 BatteryTemperature063 1;
BA_ "GenSigStartValue" SG_ 2618709748 BatteryTemperature063 50;
BA_ "GenSigILSupport" SG_ 2618709748 BatteryTemperature063 0;
BA_ "SPN" SG_ 2618709748 BatteryTemperature063 3423;
BA_ "SigType" SG_ 2618709748 BatteryTemperature062 1;
BA_ "GenSigStartValue" SG_ 2618709748 BatteryTemperature062 50;
BA_ "GenSigILSupport" SG_ 2618709748 BatteryTemperature062 0;
BA_ "SPN" SG_ 2618709748 BatteryTemperature062 3422;
BA_ "SigType" SG_ 2618709748 BatteryTemperature061 1;
BA_ "GenSigStartValue" SG_ 2618709748 BatteryTemperature061 50;
BA_ "GenSigILSupport" SG_ 2618709748 BatteryTemperature061 0;
BA_ "SPN" SG_ 2618709748 BatteryTemperature061 3421;
BA_ "SigType" SG_ 2618709748 BatteryTemperature060 1;
BA_ "GenSigStartValue" SG_ 2618709748 BatteryTemperature060 50;
BA_ "GenSigILSupport" SG_ 2618709748 BatteryTemperature060 0;
BA_ "SPN" SG_ 2618709748 BatteryTemperature060 3420;
BA_ "SigType" SG_ 2618709748 BatteryTemperature059 1;
BA_ "GenSigStartValue" SG_ 2618709748 BatteryTemperature059 50;
BA_ "GenSigILSupport" SG_ 2618709748 BatteryTemperature059 0;
BA_ "SPN" SG_ 2618709748 BatteryTemperature059 3419;
BA_ "SigType" SG_ 2618709748 BatteryTemperature058 1;
BA_ "GenSigStartValue" SG_ 2618709748 BatteryTemperature058 50;
BA_ "GenSigILSupport" SG_ 2618709748 BatteryTemperature058 0;
BA_ "SPN" SG_ 2618709748 BatteryTemperature058 3418;
BA_ "SigType" SG_ 2618709748 BatteryTemperature057 1;
BA_ "GenSigStartValue" SG_ 2618709748 BatteryTemperature057 50;
BA_ "GenSigILSupport" SG_ 2618709748 BatteryTemperature057 0;
BA_ "SPN" SG_ 2618709748 BatteryTemperature057 3417;
BA_ "SigType" SG_ 2618709748 BatteryTemperature056 1;
BA_ "GenSigStartValue" SG_ 2618709748 BatteryTemperature056 50;
BA_ "GenSigILSupport" SG_ 2618709748 BatteryTemperature056 0;
BA_ "SPN" SG_ 2618709748 BatteryTemperature056 3416;
BA_ "SigType" SG_ 2618709748 BatteryTemperature055 1;
BA_ "GenSigStartValue" SG_ 2618709748 BatteryTemperature055 50;
BA_ "GenSigILSupport" SG_ 2618709748 BatteryTemperature055 0;
BA_ "SPN" SG_ 2618709748 BatteryTemperature055 3415;
BA_ "SigType" SG_ 2618709748 BatteryTemperature054 1;
BA_ "GenSigStartValue" SG_ 2618709748 BatteryTemperature054 50;
BA_ "GenSigILSupport" SG_ 2618709748 BatteryTemperature054 0;
BA_ "SPN" SG_ 2618709748 BatteryTemperature054 3414;
BA_ "SigType" SG_ 2618709748 BatteryTemperature053 1;
BA_ "GenSigStartValue" SG_ 2618709748 BatteryTemperature053 50;
BA_ "GenSigILSupport" SG_ 2618709748 BatteryTemperature053 0;
BA_ "SPN" SG_ 2618709748 BatteryTemperature053 3413;
BA_ "SigType" SG_ 2618709748 BatteryTemperature052 1;
BA_ "GenSigStartValue" SG_ 2618709748 BatteryTemperature052 50;
BA_ "GenSigILSupport" SG_ 2618709748 BatteryTemperature052 0;
BA_ "SPN" SG_ 2618709748 BatteryTemperature052 3412;
BA_ "SigType" SG_ 2618709748 BatteryTemperature051 1;
BA_ "GenSigStartValue" SG_ 2618709748 BatteryTemperature051 50;
BA_ "GenSigILSupport" SG_ 2618709748 BatteryTemperature051 0;
BA_ "SPN" SG_ 2618709748 BatteryTemperature051 3411;
BA_ "SigType" SG_ 2618709748 BatteryTemperature050 1;
BA_ "GenSigStartValue" SG_ 2618709748 BatteryTemperature050 50;
BA_ "GenSigILSupport" SG_ 2618709748 BatteryTemperature050 0;
BA_ "SPN" SG_ 2618709748 BatteryTemperature050 3410;
BA_ "SigType" SG_ 2618709748 BatteryTemperature049 1;
BA_ "GenSigStartValue" SG_ 2618709748 BatteryTemperature049 50;
BA_ "GenSigILSupport" SG_ 2618709748 BatteryTemperature049 0;
BA_ "SPN" SG_ 2618709748 BatteryTemperature049 3409;
BA_ "SigType" SG_ 2618709748 BatteryTemperature048 1;
BA_ "GenSigStartValue" SG_ 2618709748 BatteryTemperature048 50;
BA_ "GenSigILSupport" SG_ 2618709748 BatteryTemperature048 0;
BA_ "SPN" SG_ 2618709748 BatteryTemperature048 3408;
BA_ "SigType" SG_ 2618709748 BatteryTemperature047 1;
BA_ "GenSigStartValue" SG_ 2618709748 BatteryTemperature047 50;
BA_ "GenSigILSupport" SG_ 2618709748 BatteryTemperature047 0;
BA_ "SPN" SG_ 2618709748 BatteryTemperature047 3407;
BA_ "SigType" SG_ 2618709748 BatteryTemperature046 1;
BA_ "GenSigStartValue" SG_ 2618709748 BatteryTemperature046 50;
BA_ "GenSigILSupport" SG_ 2618709748 BatteryTemperature046 0;
BA_ "SPN" SG_ 2618709748 BatteryTemperature046 3406;
BA_ "SigType" SG_ 2618709748 BatteryTemperature045 1;
BA_ "GenSigStartValue" SG_ 2618709748 BatteryTemperature045 50;
BA_ "GenSigILSupport" SG_ 2618709748 BatteryTemperature045 0;
BA_ "SPN" SG_ 2618709748 BatteryTemperature045 3405;
BA_ "SigType" SG_ 2618709748 BatteryTemperature044 1;
BA_ "GenSigStartValue" SG_ 2618709748 BatteryTemperature044 50;
BA_ "GenSigILSupport" SG_ 2618709748 BatteryTemperature044 0;
BA_ "SPN" SG_ 2618709748 BatteryTemperature044 3404;
BA_ "SigType" SG_ 2618709748 BatteryTemperature043 1;
BA_ "GenSigStartValue" SG_ 2618709748 BatteryTemperature043 50;
BA_ "GenSigILSupport" SG_ 2618709748 BatteryTemperature043 0;
BA_ "SPN" SG_ 2618709748 BatteryTemperature043 3403;
BA_ "SigType" SG_ 2618709748 BatteryTemperature042 1;
BA_ "GenSigStartValue" SG_ 2618709748 BatteryTemperature042 50;
BA_ "GenSigILSupport" SG_ 2618709748 BatteryTemperature042 0;
BA_ "SPN" SG_ 2618709748 BatteryTemperature042 3402;
BA_ "SigType" SG_ 2618709748 BatteryTemperature041 1;
BA_ "GenSigStartValue" SG_ 2618709748 BatteryTemperature041 50;
BA_ "GenSigILSupport" SG_ 2618709748 BatteryTemperature041 0;
BA_ "SPN" SG_ 2618709748 BatteryTemperature041 3401;
BA_ "SigType" SG_ 2618709748 BatteryTemperature040 1;
BA_ "GenSigStartValue" SG_ 2618709748 BatteryTemperature040 50;
BA_ "GenSigILSupport" SG_ 2618709748 BatteryTemperature040 0;
BA_ "SPN" SG_ 2618709748 BatteryTemperature040 3400;
BA_ "SigType" SG_ 2618709748 BatteryTemperature039 1;
BA_ "GenSigStartValue" SG_ 2618709748 BatteryTemperature039 50;
BA_ "GenSigILSupport" SG_ 2618709748 BatteryTemperature039 0;
BA_ "SPN" SG_ 2618709748 BatteryTemperature039 3399;
BA_ "SigType" SG_ 2618709748 BatteryTemperature038 1;
BA_ "GenSigStartValue" SG_ 2618709748 BatteryTemperature038 50;
BA_ "GenSigILSupport" SG_ 2618709748 BatteryTemperature038 0;
BA_ "SPN" SG_ 2618709748 BatteryTemperature038 3398;
BA_ "SigType" SG_ 2618709748 BatteryTemperature037 1;
BA_ "GenSigStartValue" SG_ 2618709748 BatteryTemperature037 50;
BA_ "GenSigILSupport" SG_ 2618709748 BatteryTemperature037 0;
BA_ "SPN" SG_ 2618709748 BatteryTemperature037 3397;
BA_ "SigType" SG_ 2618709748 BatteryTemperature036 1;
BA_ "GenSigStartValue" SG_ 2618709748 BatteryTemperature036 50;
BA_ "GenSigILSupport" SG_ 2618709748 BatteryTemperature036 0;
BA_ "SPN" SG_ 2618709748 BatteryTemperature036 3396;
BA_ "SigType" SG_ 2618709748 BatteryTemperature035 1;
BA_ "GenSigStartValue" SG_ 2618709748 BatteryTemperature035 50;
BA_ "GenSigILSupport" SG_ 2618709748 BatteryTemperature035 0;
BA_ "SPN" SG_ 2618709748 BatteryTemperature035 3395;
BA_ "SigType" SG_ 2618709748 BatteryTemperature034 1;
BA_ "GenSigStartValue" SG_ 2618709748 BatteryTemperature034 50;
BA_ "GenSigILSupport" SG_ 2618709748 BatteryTemperature034 0;
BA_ "SPN" SG_ 2618709748 BatteryTemperature034 3394;
BA_ "SigType" SG_ 2618709748 BatteryTemperature033 1;
BA_ "GenSigStartValue" SG_ 2618709748 BatteryTemperature033 50;
BA_ "GenSigILSupport" SG_ 2618709748 BatteryTemperature033 0;
BA_ "SPN" SG_ 2618709748 BatteryTemperature033 3393;
BA_ "SigType" SG_ 2618709748 BatteryTemperature032 1;
BA_ "GenSigStartValue" SG_ 2618709748 BatteryTemperature032 50;
BA_ "GenSigILSupport" SG_ 2618709748 BatteryTemperature032 0;
BA_ "SPN" SG_ 2618709748 BatteryTemperature032 3392;
BA_ "SigType" SG_ 2618709748 BatteryTemperature031 1;
BA_ "GenSigStartValue" SG_ 2618709748 BatteryTemperature031 50;
BA_ "GenSigILSupport" SG_ 2618709748 BatteryTemperature031 0;
BA_ "SPN" SG_ 2618709748 BatteryTemperature031 3391;
BA_ "SigType" SG_ 2618709748 BatteryTemperature030 1;
BA_ "GenSigStartValue" SG_ 2618709748 BatteryTemperature030 50;
BA_ "GenSigILSupport" SG_ 2618709748 BatteryTemperature030 0;
BA_ "SPN" SG_ 2618709748 BatteryTemperature030 3390;
BA_ "SigType" SG_ 2618709748 BatteryTemperature029 1;
BA_ "GenSigStartValue" SG_ 2618709748 BatteryTemperature029 50;
BA_ "GenSigILSupport" SG_ 2618709748 BatteryTemperature029 0;
BA_ "SPN" SG_ 2618709748 BatteryTemperature029 3389;
BA_ "SigType" SG_ 2618709748 BatteryTemperature028 1;
BA_ "GenSigStartValue" SG_ 2618709748 BatteryTemperature028 50;
BA_ "GenSigILSupport" SG_ 2618709748 BatteryTemperature028 0;
BA_ "SPN" SG_ 2618709748 BatteryTemperature028 3388;
BA_ "SigType" SG_ 2618709748 BatteryTemperature027 1;
BA_ "GenSigStartValue" SG_ 2618709748 BatteryTemperature027 50;
BA_ "GenSigILSupport" SG_ 2618709748 BatteryTemperature027 0;
BA_ "SPN" SG_ 2618709748 BatteryTemperature027 3387;
BA_ "SigType" SG_ 2618709748 BatteryTemperature026 1;
BA_ "GenSigStartValue" SG_ 2618709748 BatteryTemperature026 50;
BA_ "GenSigILSupport" SG_ 2618709748 BatteryTemperature026 0;
BA_ "SPN" SG_ 2618709748 BatteryTemperature026 3386;
BA_ "SigType" SG_ 2618709748 BatteryTemperature025 1;
BA_ "GenSigStartValue" SG_ 2618709748 BatteryTemperature025 50;
BA_ "GenSigILSupport" SG_ 2618709748 BatteryTemperature025 0;
BA_ "SPN" SG_ 2618709748 BatteryTemperature025 3385;
BA_ "SigType" SG_ 2618709748 BatteryTemperature024 1;
BA_ "GenSigStartValue" SG_ 2618709748 BatteryTemperature024 50;
BA_ "GenSigILSupport" SG_ 2618709748 BatteryTemperature024 0;
BA_ "SPN" SG_ 2618709748 BatteryTemperature024 3384;
BA_ "SigType" SG_ 2618709748 BatteryTemperature023 1;
BA_ "GenSigStartValue" SG_ 2618709748 BatteryTemperature023 50;
BA_ "GenSigILSupport" SG_ 2618709748 BatteryTemperature023 0;
BA_ "SPN" SG_ 2618709748 BatteryTemperature023 3383;
BA_ "SigType" SG_ 2618709748 BatteryTemperature022 1;
BA_ "GenSigStartValue" SG_ 2618709748 BatteryTemperature022 50;
BA_ "GenSigILSupport" SG_ 2618709748 BatteryTemperature022 0;
BA_ "SPN" SG_ 2618709748 BatteryTemperature022 3382;
BA_ "SigType" SG_ 2618709748 BatteryTemperature021 1;
BA_ "GenSigStartValue" SG_ 2618709748 BatteryTemperature021 50;
BA_ "GenSigILSupport" SG_ 2618709748 BatteryTemperature021 0;
BA_ "SPN" SG_ 2618709748 BatteryTemperature021 3381;
BA_ "SigType" SG_ 2618709748 BatteryTemperature020 1;
BA_ "GenSigStartValue" SG_ 2618709748 BatteryTemperature020 50;
BA_ "GenSigILSupport" SG_ 2618709748 BatteryTemperature020 0;
BA_ "SPN" SG_ 2618709748 BatteryTemperature020 3380;
BA_ "SigType" SG_ 2618709748 BatteryTemperature019 1;
BA_ "GenSigStartValue" SG_ 2618709748 BatteryTemperature019 50;
BA_ "GenSigILSupport" SG_ 2618709748 BatteryTemperature019 0;
BA_ "SPN" SG_ 2618709748 BatteryTemperature019 3379;
BA_ "SigType" SG_ 2618709748 BatteryTemperature018 1;
BA_ "GenSigStartValue" SG_ 2618709748 BatteryTemperature018 50;
BA_ "GenSigILSupport" SG_ 2618709748 BatteryTemperature018 0;
BA_ "SPN" SG_ 2618709748 BatteryTemperature018 3378;
BA_ "SigType" SG_ 2618709748 BatteryTemperature017 1;
BA_ "GenSigStartValue" SG_ 2618709748 BatteryTemperature017 50;
BA_ "GenSigILSupport" SG_ 2618709748 BatteryTemperature017 0;
BA_ "SPN" SG_ 2618709748 BatteryTemperature017 3377;
BA_ "SigType" SG_ 2618709748 BatteryTemperature016 1;
BA_ "GenSigStartValue" SG_ 2618709748 BatteryTemperature016 50;
BA_ "GenSigILSupport" SG_ 2618709748 BatteryTemperature016 0;
BA_ "SPN" SG_ 2618709748 BatteryTemperature016 3376;
BA_ "SigType" SG_ 2618709748 BatteryTemperature015 1;
BA_ "GenSigStartValue" SG_ 2618709748 BatteryTemperature015 50;
BA_ "GenSigILSupport" SG_ 2618709748 BatteryTemperature015 0;
BA_ "SPN" SG_ 2618709748 BatteryTemperature015 3375;
BA_ "SigType" SG_ 2618709748 BatteryTemperature014 1;
BA_ "GenSigStartValue" SG_ 2618709748 BatteryTemperature014 50;
BA_ "GenSigILSupport" SG_ 2618709748 BatteryTemperature014 0;
BA_ "SPN" SG_ 2618709748 BatteryTemperature014 3374;
BA_ "SigType" SG_ 2618709748 BatteryTemperature013 1;
BA_ "GenSigStartValue" SG_ 2618709748 BatteryTemperature013 50;
BA_ "GenSigILSupport" SG_ 2618709748 BatteryTemperature013 0;
BA_ "SPN" SG_ 2618709748 BatteryTemperature013 3373;
BA_ "SigType" SG_ 2618709748 BatteryTemperature012 1;
BA_ "GenSigStartValue" SG_ 2618709748 BatteryTemperature012 50;
BA_ "GenSigILSupport" SG_ 2618709748 BatteryTemperature012 0;
BA_ "SPN" SG_ 2618709748 BatteryTemperature012 3372;
BA_ "SigType" SG_ 2618709748 BatteryTemperature011 1;
BA_ "GenSigStartValue" SG_ 2618709748 BatteryTemperature011 50;
BA_ "GenSigILSupport" SG_ 2618709748 BatteryTemperature011 0;
BA_ "SPN" SG_ 2618709748 BatteryTemperature011 3371;
BA_ "SigType" SG_ 2618709748 BatteryTemperature010 1;
BA_ "GenSigStartValue" SG_ 2618709748 BatteryTemperature010 50;
BA_ "GenSigILSupport" SG_ 2618709748 BatteryTemperature010 0;
BA_ "SPN" SG_ 2618709748 BatteryTemperature010 3370;
BA_ "SigType" SG_ 2618709748 BatteryTemperature009 1;
BA_ "GenSigStartValue" SG_ 2618709748 BatteryTemperature009 50;
BA_ "GenSigILSupport" SG_ 2618709748 BatteryTemperature009 0;
BA_ "SPN" SG_ 2618709748 BatteryTemperature009 3369;
BA_ "SigType" SG_ 2618709748 BatteryTemperature008 1;
BA_ "GenSigStartValue" SG_ 2618709748 BatteryTemperature008 50;
BA_ "GenSigILSupport" SG_ 2618709748 BatteryTemperature008 0;
BA_ "SPN" SG_ 2618709748 BatteryTemperature008 3368;
BA_ "SigType" SG_ 2618709748 BatteryTemperature007 1;
BA_ "GenSigStartValue" SG_ 2618709748 BatteryTemperature007 50;
BA_ "GenSigILSupport" SG_ 2618709748 BatteryTemperature007 0;
BA_ "SPN" SG_ 2618709748 BatteryTemperature007 3367;
BA_ "SigType" SG_ 2618709748 BatteryTemperature006 1;
BA_ "GenSigStartValue" SG_ 2618709748 BatteryTemperature006 50;
BA_ "GenSigILSupport" SG_ 2618709748 BatteryTemperature006 0;
BA_ "SPN" SG_ 2618709748 BatteryTemperature006 3366;
BA_ "SigType" SG_ 2618709748 BatteryTemperature005 1;
BA_ "GenSigStartValue" SG_ 2618709748 BatteryTemperature005 50;
BA_ "GenSigILSupport" SG_ 2618709748 BatteryTemperature005 0;
BA_ "SPN" SG_ 2618709748 BatteryTemperature005 3365;
BA_ "SigType" SG_ 2618709748 BatteryTemperature004 1;
BA_ "GenSigStartValue" SG_ 2618709748 BatteryTemperature004 50;
BA_ "GenSigILSupport" SG_ 2618709748 BatteryTemperature004 0;
BA_ "SPN" SG_ 2618709748 BatteryTemperature004 3364;
BA_ "SigType" SG_ 2618709748 BatteryTemperature003 1;
BA_ "GenSigStartValue" SG_ 2618709748 BatteryTemperature003 50;
BA_ "GenSigILSupport" SG_ 2618709748 BatteryTemperature003 0;
BA_ "SPN" SG_ 2618709748 BatteryTemperature003 3363;
BA_ "SigType" SG_ 2618709748 BatteryTemperature002 1;
BA_ "GenSigStartValue" SG_ 2618709748 BatteryTemperature002 50;
BA_ "GenSigILSupport" SG_ 2618709748 BatteryTemperature002 0;
BA_ "SPN" SG_ 2618709748 BatteryTemperature002 3362;
BA_ "GenSigStartValue" SG_ 2618709748 BatteryTemperature001 50;
BA_ "SigType" SG_ 2618709748 BatteryTemperature001 1;
BA_ "GenSigILSupport" SG_ 2618709748 BatteryTemperature001 0;
BA_ "SPN" SG_ 2618709748 BatteryTemperature001 3361;
VAL_ 2283795542 Timeout_BSD 3 "Not Available" 2 "Untrusted" 1 "Timeout" 0 "Normal" ;
VAL_ 2283795542 Timeout_BST 3 "Not Available" 2 "Untrusted" 1 "Timeout" 0 "Normal" ;
VAL_ 2283795542 Timeout_BSM 3 "Not Available" 2 "Untrusted" 1 "Timeout" 0 "Normal" ;
VAL_ 2283795542 Timeout_BCS 3 "Not Available" 2 "Untrusted" 1 "Timeout" 0 "Normal" ;
VAL_ 2283795542 Timeout_BRO 3 "Not Available" 2 "Untrusted" 1 "Timeout" 0 "Normal" ;
VAL_ 2283795542 Timeout_BCP 3 "Not Available" 2 "Untrusted" 1 "Timeout" 0 "Normal" ;
VAL_ 2283795542 Timeout_BRM 3 "Not Available" 2 "Untrusted" 1 "Timeout" 0 "Normal" ;
VAL_ 2283689716 Timeout_CSD 3 "Not Available" 2 "Untrusted" 1 "Timeout" 0 "Normal" ;
VAL_ 2283689716 Timeout_CST 3 "Not Available" 2 "Untrusted" 1 "Timeout" 0 "Normal" ;
VAL_ 2283689716 Timeout_CCS 3 "Not Available" 2 "Untrusted" 1 "Timeout" 0 "Normal" ;
VAL_ 2283689716 Timeout_CRO 3 "Not Available" 2 "Untrusted" 1 "Timeout" 0 "Normal" ;
VAL_ 2283689716 Timeout_CTS_CML 3 "Not Available" 2 "Untrusted" 1 "Timeout" 0 "Normal" ;
VAL_ 2283689716 Timeout_CRM_Recognized 3 "Not Available" 2 "Untrusted" 1 "Timeout" 0 "Normal" ;
VAL_ 2283689716 Timeout_CRM_Unrecognized 3 "Not Available" 2 "Untrusted" 1 "Timeout" 0 "Normal" ;
VAL_ 2417685590 CrgSuspError_AbnormalVoltage 3 "Not Available" 2 "Untrusted" 1 "Abnormal" 0 "Normal" ;
VAL_ 2417685590 CrgSuspError_CurrentMismatch 3 "Not Available" 2 "Untrusted" 1 "Abnormal" 0 "Normal" ;
VAL_ 2417685590 CrgSuspFault_OtherFault 3 "Not Available" 2 "Untrusted" 1 "Fault" 0 "Normal" ;
VAL_ 2417685590 CrgSuspFault_SuddenStop 3 "Not Available" 2 "Untrusted" 1 "Fault" 0 "Normal" ;
VAL_ 2417685590 CrgSuspFault_CannotSupply 3 "Not Available" 2 "Untrusted" 1 "Fault" 0 "Normal" ;
VAL_ 2417685590 CrgSuspFault_CrgTempInt 3 "Not Available" 2 "Untrusted" 1 "Fault" 0 "Normal" ;
VAL_ 2417685590 CrgSuspFault_ChargeConn 3 "Not Available" 2 "Untrusted" 1 "Fault" 0 "Normal" ;
VAL_ 2417685590 CrgSuspFault_CrgTemp 3 "Not Available" 2 "Untrusted" 1 "Fault" 0 "Normal" ;
VAL_ 2417685590 CrgSuspCause_BmsActiveSusp 3 "Not Available" 2 "Untrusted" 1 "BMS Suspension" 0 "Normal" ;
VAL_ 2417685590 CrgSuspCause_Fault 3 "Not Available" 2 "Untrusted" 1 "Fault" 0 "Normal" ;
VAL_ 2417685590 CrgSuspCause_Artificial 3 "Not Available" 2 "Untrusted" 1 "Artificial Suspension" 0 "Normal" ;
VAL_ 2417685590 CrgSuspCause_ChargerCond 3 "Not Available" 2 "Untrusted" 1 "Condition Reached" 0 "Normal" ;
VAL_ 2417579764 BmsSuspError_AbnormalVoltage 3 "Not Available" 2 "Untrusted" 1 "Abnormal" 0 "Normal" ;
VAL_ 2417579764 BmsSuspError_ExcessiveCurrent 3 "Not Available" 2 "Untrusted" 1 "Abnormal" 0 "Normal" ;
VAL_ 2417579764 BmsSuspFault_OtherFaults 3 "Not Available" 2 "Untrusted" 1 "Fault" 0 "Normal" ;
VAL_ 2417579764 BmsSuspFault_BmsTemp 3 "Not Available" 2 "Untrusted" 1 "Fault" 0 "Normal" ;
VAL_ 2417579764 BmsSuspFault_VoltageDetection 3 "Not Available" 2 "Untrusted" 1 "Fault" 0 "Normal" ;
VAL_ 2417579764 BmsSuspFault_VoltageRelay 3 "Not Available" 2 "Untrusted" 1 "Fault" 0 "Normal" ;
VAL_ 2417579764 BmsSuspFault_BatteryTemp 3 "Not Available" 2 "Untrusted" 1 "Fault" 0 "Normal" ;
VAL_ 2417579764 BmsSuspFault_ChargeConn 3 "Not Available" 2 "Untrusted" 1 "Fault" 0 "Normal" ;
VAL_ 2417579764 BmsSuspFault_OutputConnTemp 3 "Not Available" 2 "Untrusted" 1 "Fault" 0 "Normal" ;
VAL_ 2417579764 BmsSuspFault_Insulation 3 "Not Available" 2 "Untrusted" 1 "Fault" 0 "Normal" ;
VAL_ 2417579764 BmsSuspCause_ActiveSuspend 3 "Not Available" 2 "Untrusted" 1 "Reached" 0 "Not Reached" ;
VAL_ 2417579764 BmsSuspCause_SingleVoltage 3 "Not Available" 2 "Untrusted" 1 "Reached" 0 "Not Reached" ;
VAL_ 2417579764 BmsSuspCause_TotalVoltage 3 "Not Available" 2 "Untrusted" 1 "Reached" 0 "Not Reached" ;
VAL_ 2417579764 BmsSuspCause_SOC 3 "Not Available" 2 "Untrusted" 1 "Reached" 0 "Not Reached" ;
